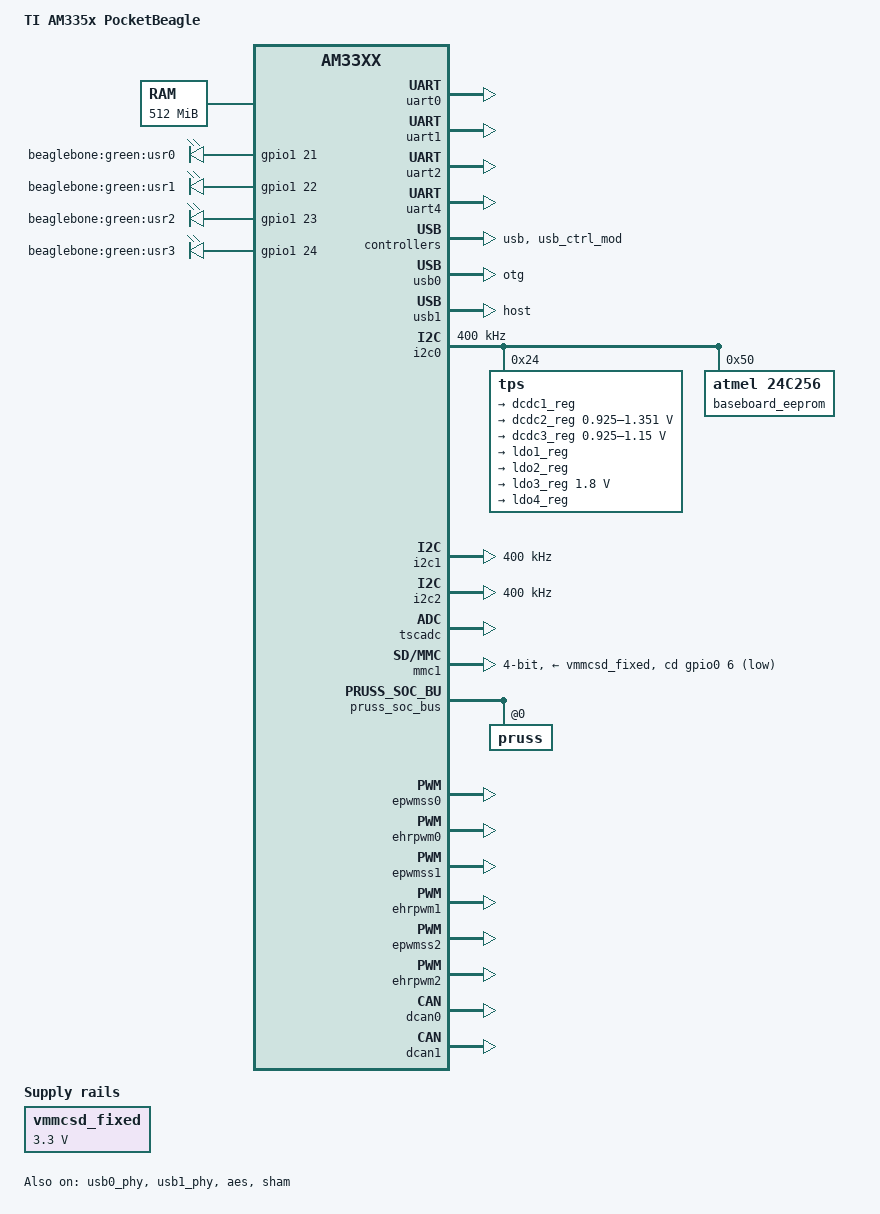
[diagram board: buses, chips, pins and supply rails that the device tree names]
/*
 * Copyright (C) 2012 Texas Instruments Incorporated - http://www.ti.com/
 *
 * This program is free software; you can redistribute it and/or modify
 * it under the terms of the GNU General Public License version 2 as
 * published by the Free Software Foundation.
 */

#include "am33xx.dtsi"

/ {
	model = "TI AM335x PocketBeagle";
	compatible = "ti,am335x-pocketbeagle", "ti,am335x-bone", "ti,am33xx";

	cpus {
		cpu@0 {
			cpu0-supply = <&dcdc2_reg>;
		};
	};

	memory@80000000 {
		device_type = "memory";
		reg = <0x80000000 0x20000000>; /* 512 MB */
	};

	chosen {
		stdout-path = &uart0;
	};

	leds {
		pinctrl-names = "default", "sleep";
		pinctrl-0 = <&user_leds_default>;
		pinctrl-1 = <&user_leds_sleep>;

		compatible = "gpio-leds";

		led@2 {
			label = "beaglebone:green:usr0";
			gpios = <&gpio1 21 GPIO_ACTIVE_HIGH>;
			linux,default-trigger = "heartbeat";
			default-state = "off";
		};

		led@3 {
			label = "beaglebone:green:usr1";
			gpios = <&gpio1 22 GPIO_ACTIVE_HIGH>;
			linux,default-trigger = "mmc0";
			default-state = "off";
		};

		led@4 {
			label = "beaglebone:green:usr2";
			gpios = <&gpio1 23 GPIO_ACTIVE_HIGH>;
			linux,default-trigger = "cpu0";
			default-state = "off";
		};

		led@5 {
			label = "beaglebone:green:usr3";
			gpios = <&gpio1 24 GPIO_ACTIVE_HIGH>;
			linux,default-trigger = "mmc1";
			default-state = "off";
		};
	};

	vmmcsd_fixed: fixedregulator0 {
		compatible = "regulator-fixed";
		regulator-name = "vmmcsd_fixed";
		regulator-min-microvolt = <3300000>;
		regulator-max-microvolt = <3300000>;
	};
};

&cpu0_opp_table {
	/*
	* All PG 2.0 silicon may not support 1GHz but some of the early
	* BeagleBone Blacks have PG 2.0 silicon which is guaranteed
	* to support 1GHz OPP so enable it for PG 2.0 on this board.
	*/
	oppnitro-1000000000 {
		opp-supported-hw = <0x06 0x0100>;
	};
};

&am33xx_pinmux {
	user_leds_default: user_leds_default {
		pinctrl-single,pins = <
			AM33XX_IOPAD(0x0854, PIN_OUTPUT_PULLDOWN | MUX_MODE7)	/* gpmc_a5.gpio1_21 */
			AM33XX_IOPAD(0x0858, PIN_OUTPUT_PULLUP | MUX_MODE7)	/* gpmc_a6.gpio1_22 */
			AM33XX_IOPAD(0x085c, PIN_OUTPUT_PULLDOWN | MUX_MODE7)	/* gpmc_a7.gpio1_23 */
			AM33XX_IOPAD(0x0860, PIN_OUTPUT_PULLUP | MUX_MODE7)	/* gpmc_a8.gpio1_24 */
		>;
	};

	user_leds_sleep: user_leds_sleep {
		pinctrl-single,pins = <
			AM33XX_IOPAD(0x0854, PIN_INPUT_PULLDOWN | MUX_MODE7)	/* gpmc_a5.gpio1_21 */
			AM33XX_IOPAD(0x0858, PIN_INPUT_PULLDOWN | MUX_MODE7)	/* gpmc_a6.gpio1_22 */
			AM33XX_IOPAD(0x085c, PIN_INPUT_PULLDOWN | MUX_MODE7)	/* gpmc_a7.gpio1_23 */
			AM33XX_IOPAD(0x0860, PIN_INPUT_PULLDOWN | MUX_MODE7)	/* gpmc_a8.gpio1_24 */
		>;
	};

	i2c0_pins: pinmux_i2c0_pins {
		pinctrl-single,pins = <
			AM33XX_IOPAD(0x0988, PIN_INPUT_PULLUP | MUX_MODE0)	/* i2c0_sda.i2c0_sda */
			AM33XX_IOPAD(0x098c, PIN_INPUT_PULLUP | MUX_MODE0)	/* i2c0_scl.i2c0_scl */
		>;
	};

	mmc0_pins: pinmux_mmc0_pins {
		pinctrl-single,pins = <
			AM33XX_IOPAD(0x0960, PIN_INPUT | MUX_MODE7) /* GPIO0_6 */
		>;
	};

	/************************/
	/* P1 Header */
	/************************/

	/* P1_01                VIN-AC */

	/* P1_02 (ZCZ ball R5) gpio2_23 */
	P1_02_default_pin: pinmux_P1_02_default_pin { pinctrl-single,pins = <
		AM33XX_IOPAD(0x08e4, PIN_INPUT | MUX_MODE7) >; };			/* lcd_hsync.gpio2_23 */
	P1_02_gpio_pin: pinmux_P1_02_gpio_pin { pinctrl-single,pins = <
		AM33XX_IOPAD(0x08e4, PIN_OUTPUT | INPUT_EN | MUX_MODE7) >; };		/* lcd_hsync.gpio2_23 */
	P1_02_gpio_pu_pin: pinmux_P1_02_gpio_pu_pin { pinctrl-single,pins = <
		AM33XX_IOPAD(0x08e4, PIN_OUTPUT_PULLUP | INPUT_EN | MUX_MODE7) >; };	/* lcd_hsync.gpio2_23 */
	P1_02_gpio_pd_pin: pinmux_P1_02_gpio_pd_pin { pinctrl-single,pins = <
		AM33XX_IOPAD(0x08e4, PIN_OUTPUT_PULLDOWN | INPUT_EN | MUX_MODE7) >; };	/* lcd_hsync.gpio2_23 */
	P1_02_gpio_input_pin: pinmux_P1_02_gpio_input_pin { pinctrl-single,pins = <
		AM33XX_IOPAD(0x08e4, PIN_INPUT | MUX_MODE7) >; };			/* lcd_hsync.gpio2_23 */
	P1_02_pruout_pin: pinmux_P1_02_pruout_pin { pinctrl-single,pins = <
		AM33XX_IOPAD(0x08e4, PIN_OUTPUT_PULLDOWN | INPUT_EN | MUX_MODE5) >; };	/* lcd_hsync.pru1_out9 */
	P1_02_pruin_pin: pinmux_P1_02_pruin_pin { pinctrl-single,pins = <
		AM33XX_IOPAD(0x08e4, PIN_INPUT | MUX_MODE6) >; };			/* lcd_hsync.pru1_in9 */

	/* P1_03 (ZCZ ball F15)  usb1_vbus_out         */

	/* P1_04 (ZCZ ball R6) gpio2_25 */
	P1_04_default_pin: pinmux_P1_04_default_pin { pinctrl-single,pins = <
		AM33XX_IOPAD(0x08ec, PIN_OUTPUT_PULLDOWN | INPUT_EN | MUX_MODE7) >; };	/* lcd_ac_bias_en.gpio2_25 */
	P1_04_gpio_pin: pinmux_P1_04_gpio_pin { pinctrl-single,pins = <
		AM33XX_IOPAD(0x08ec, PIN_OUTPUT | INPUT_EN | MUX_MODE7) >; };		/* lcd_ac_bias_en.gpio2_25 */
	P1_04_gpio_pu_pin: pinmux_P1_04_gpio_pu_pin { pinctrl-single,pins = <
		AM33XX_IOPAD(0x08ec, PIN_OUTPUT_PULLUP | INPUT_EN | MUX_MODE7) >; };	/* lcd_ac_bias_en.gpio2_25 */
	P1_04_gpio_pd_pin: pinmux_P1_04_gpio_pd_pin { pinctrl-single,pins = <
		AM33XX_IOPAD(0x08ec, PIN_OUTPUT_PULLDOWN | INPUT_EN | MUX_MODE7) >; };	/* lcd_ac_bias_en.gpio2_25 */
	P1_04_gpio_input_pin: pinmux_P1_04_gpio_input_pin { pinctrl-single,pins = <
		AM33XX_IOPAD(0x08ec, PIN_INPUT | MUX_MODE7) >; };			/* lcd_ac_bias_en.gpio2_25 */
	P1_04_pruout_pin: pinmux_P1_04_pruout_pin { pinctrl-single,pins = <
		AM33XX_IOPAD(0x08ec, PIN_OUTPUT_PULLDOWN | INPUT_EN | MUX_MODE5) >; };	/* lcd_ac_bias_en.pru1_out11 */
	P1_04_pruin_pin: pinmux_P1_04_pruin_pin { pinctrl-single,pins = <
		AM33XX_IOPAD(0x08ec, PIN_INPUT | MUX_MODE6) >; };			/* lcd_ac_bias_en.pru1_in11 */

	/* P1_05 (ZCZ ball T18)  usb1_vbus_in         */

	/* P1_06 (ZCZ ball A16) spi0_cs0 */
	P1_06_default_pin: pinmux_P1_06_default_pin { pinctrl-single,pins = <
		AM33XX_IOPAD(0x095c, PIN_OUTPUT_PULLUP | INPUT_EN | MUX_MODE0) >; };	/* spi0_cs0.spi0_cs0 */
	P1_06_gpio_pin: pinmux_P1_06_gpio_pin { pinctrl-single,pins = <
		AM33XX_IOPAD(0x095c, PIN_OUTPUT | INPUT_EN | MUX_MODE7) >; };		/* spi0_cs0.gpio0_5 */
	P1_06_gpio_pu_pin: pinmux_P1_06_gpio_pu_pin { pinctrl-single,pins = <
		AM33XX_IOPAD(0x095c, PIN_OUTPUT_PULLUP | INPUT_EN | MUX_MODE7) >; };	/* spi0_cs0.gpio0_5 */
	P1_06_gpio_pd_pin: pinmux_P1_06_gpio_pd_pin { pinctrl-single,pins = <
		AM33XX_IOPAD(0x095c, PIN_OUTPUT_PULLDOWN | INPUT_EN | MUX_MODE7) >; };	/* spi0_cs0.gpio0_5 */
	P1_06_gpio_input_pin: pinmux_P1_06_gpio_input_pin { pinctrl-single,pins = <
		AM33XX_IOPAD(0x095c, PIN_INPUT | MUX_MODE7) >; };			/* spi0_cs0.gpio0_5 */
	P1_06_spi_cs_pin: pinmux_P1_06_spi_cs_pin { pinctrl-single,pins = <
		AM33XX_IOPAD(0x095c, PIN_OUTPUT_PULLUP | INPUT_EN | MUX_MODE0) >; };	/* spi0_cs0.spi0_cs0 */
	P1_06_i2c_pin: pinmux_P1_06_i2c_pin { pinctrl-single,pins = <
		AM33XX_IOPAD(0x095c, PIN_OUTPUT_PULLUP | INPUT_EN | MUX_MODE2) >; };	/* spi0_cs0.i2c1_scl */
	P1_06_pwm_pin: pinmux_P1_06_pwm_pin { pinctrl-single,pins = <
		AM33XX_IOPAD(0x095c, PIN_OUTPUT_PULLDOWN | INPUT_EN | MUX_MODE3) >; };	/* spi0_cs0.ehrpwm0_synci */
	P1_06_pru_uart_pin: pinmux_P1_06_pru_uart_pin { pinctrl-single,pins = <
		AM33XX_IOPAD(0x095c, PIN_OUTPUT_PULLUP | INPUT_EN | MUX_MODE4) >; };	/* spi0_cs0.pr1_uart0_txd */

	/* P1_07                VIN-USB */

	/* P1_08 (ZCZ ball A17) spi0_sclk */
	P1_08_default_pin: pinmux_P1_08_default_pin { pinctrl-single,pins = <
		AM33XX_IOPAD(0x0950, PIN_OUTPUT_PULLUP | INPUT_EN | MUX_MODE0) >; };	/* spi0_sclk.spi0_sclk */
	P1_08_gpio_pin: pinmux_P1_08_gpio_pin { pinctrl-single,pins = <
		AM33XX_IOPAD(0x0950, PIN_OUTPUT | INPUT_EN | MUX_MODE7) >; };		/* spi0_sclk.gpio0_2 */
	P1_08_gpio_pu_pin: pinmux_P1_08_gpio_pu_pin { pinctrl-single,pins = <
		AM33XX_IOPAD(0x0950, PIN_OUTPUT_PULLUP | INPUT_EN | MUX_MODE7) >; };	/* spi0_sclk.gpio0_2 */
	P1_08_gpio_pd_pin: pinmux_P1_08_gpio_pd_pin { pinctrl-single,pins = <
		AM33XX_IOPAD(0x0950, PIN_OUTPUT_PULLDOWN | INPUT_EN | MUX_MODE7) >; };	/* spi0_sclk.gpio0_2 */
	P1_08_gpio_input_pin: pinmux_P1_08_gpio_input_pin { pinctrl-single,pins = <
		AM33XX_IOPAD(0x0950, PIN_INPUT | MUX_MODE7) >; };			/* spi0_sclk.gpio0_2 */
	P1_08_spi_sclk_pin: pinmux_P1_08_spi_sclk_pin { pinctrl-single,pins = <
		AM33XX_IOPAD(0x0950, PIN_OUTPUT_PULLUP | INPUT_EN | MUX_MODE0) >; };	/* spi0_sclk.spi0_sclk */
	P1_08_uart_pin: pinmux_P1_08_uart_pin { pinctrl-single,pins = <
		AM33XX_IOPAD(0x0950, PIN_OUTPUT_PULLUP | INPUT_EN | MUX_MODE1) >; };	/* spi0_sclk.uart2_rxd */
	P1_08_i2c_pin: pinmux_P1_08_i2c_pin { pinctrl-single,pins = <
		AM33XX_IOPAD(0x0950, PIN_OUTPUT_PULLUP | INPUT_EN | MUX_MODE2) >; };	/* spi0_sclk.i2c2_sda */
	P1_08_pwm_pin: pinmux_P1_08_pwm_pin { pinctrl-single,pins = <
		AM33XX_IOPAD(0x0950, PIN_OUTPUT_PULLDOWN | INPUT_EN | MUX_MODE3) >; };	/* spi0_sclk.ehrpwm0a */
	P1_08_pru_uart_pin: pinmux_P1_08_pru_uart_pin { pinctrl-single,pins = <
		AM33XX_IOPAD(0x0950, PIN_OUTPUT_PULLUP | INPUT_EN | MUX_MODE4) >; };	/* spi0_sclk.pr1_uart0_cts_n */

	/* P1_09 (ZCZ ball R18)  USB1-DN         */

	/* P1_10 (ZCZ ball B17) spi0_d0 */
	P1_10_default_pin: pinmux_P1_10_default_pin { pinctrl-single,pins = <
		AM33XX_IOPAD(0x0954, PIN_OUTPUT_PULLUP | INPUT_EN | MUX_MODE0) >; };	/* spi0_d0.spi0_d0 */
	P1_10_gpio_pin: pinmux_P1_10_gpio_pin { pinctrl-single,pins = <
		AM33XX_IOPAD(0x0954, PIN_OUTPUT | INPUT_EN | MUX_MODE7) >; };		/* spi0_d0.gpio0_3 */
	P1_10_gpio_pu_pin: pinmux_P1_10_gpio_pu_pin { pinctrl-single,pins = <
		AM33XX_IOPAD(0x0954, PIN_OUTPUT_PULLUP | INPUT_EN | MUX_MODE7) >; };	/* spi0_d0.gpio0_3 */
	P1_10_gpio_pd_pin: pinmux_P1_10_gpio_pd_pin { pinctrl-single,pins = <
		AM33XX_IOPAD(0x0954, PIN_OUTPUT_PULLDOWN | INPUT_EN | MUX_MODE7) >; };	/* spi0_d0.gpio0_3 */
	P1_10_gpio_input_pin: pinmux_P1_10_gpio_input_pin { pinctrl-single,pins = <
		AM33XX_IOPAD(0x0954, PIN_INPUT | MUX_MODE7) >; };			/* spi0_d0.gpio0_3 */
	P1_10_spi_pin: pinmux_P1_10_spi_pin { pinctrl-single,pins = <
		AM33XX_IOPAD(0x0954, PIN_OUTPUT_PULLUP | INPUT_EN | MUX_MODE0) >; };	/* spi0_d0.spi0_d0 */
	P1_10_uart_pin: pinmux_P1_10_uart_pin { pinctrl-single,pins = <
		AM33XX_IOPAD(0x0954, PIN_OUTPUT_PULLUP | INPUT_EN | MUX_MODE1) >; };	/* spi0_d0.uart2_txd */
	P1_10_i2c_pin: pinmux_P1_10_i2c_pin { pinctrl-single,pins = <
		AM33XX_IOPAD(0x0954, PIN_OUTPUT_PULLUP | INPUT_EN | MUX_MODE2) >; };	/* spi0_d0.i2c2_scl */
	P1_10_pwm_pin: pinmux_P1_10_pwm_pin { pinctrl-single,pins = <
		AM33XX_IOPAD(0x0954, PIN_OUTPUT_PULLDOWN | INPUT_EN | MUX_MODE3) >; };	/* spi0_d0.ehrpwm0b */
	P1_10_pru_uart_pin: pinmux_P1_10_pru_uart_pin { pinctrl-single,pins = <
		AM33XX_IOPAD(0x0954, PIN_OUTPUT_PULLUP | INPUT_EN | MUX_MODE4) >; };	/* spi0_d0.pr1_uart0_rts_n */

	/* P1_11 (ZCZ ball R17)  USB1-DP         */

	/* P1_12 (ZCZ ball B16) spi0_d1 */
	P1_12_default_pin: pinmux_P1_12_default_pin { pinctrl-single,pins = <
		AM33XX_IOPAD(0x0958, PIN_OUTPUT_PULLUP | INPUT_EN | MUX_MODE0) >; };	/* spi0_d1.spi0_d1 */
	P1_12_gpio_pin: pinmux_P1_12_gpio_pin { pinctrl-single,pins = <
		AM33XX_IOPAD(0x0958, PIN_OUTPUT | INPUT_EN | MUX_MODE7) >; };		/* spi0_d1.gpio0_4 */
	P1_12_gpio_pu_pin: pinmux_P1_12_gpio_pu_pin { pinctrl-single,pins = <
		AM33XX_IOPAD(0x0958, PIN_OUTPUT_PULLUP | INPUT_EN | MUX_MODE7) >; };	/* spi0_d1.gpio0_4 */
	P1_12_gpio_pd_pin: pinmux_P1_12_gpio_pd_pin { pinctrl-single,pins = <
		AM33XX_IOPAD(0x0958, PIN_OUTPUT_PULLDOWN | INPUT_EN | MUX_MODE7) >; };	/* spi0_d1.gpio0_4 */
	P1_12_gpio_input_pin: pinmux_P1_12_gpio_input_pin { pinctrl-single,pins = <
		AM33XX_IOPAD(0x0958, PIN_INPUT | MUX_MODE7) >; };			/* spi0_d1.gpio0_4 */
	P1_12_spi_pin: pinmux_P1_12_spi_pin { pinctrl-single,pins = <
		AM33XX_IOPAD(0x0958, PIN_OUTPUT_PULLUP | INPUT_EN | MUX_MODE0) >; };	/* spi0_d1.spi0_d1 */
	P1_12_i2c_pin: pinmux_P1_12_i2c_pin { pinctrl-single,pins = <
		AM33XX_IOPAD(0x0958, PIN_OUTPUT_PULLUP | INPUT_EN | MUX_MODE2) >; };	/* spi0_d1.i2c1_sda */
	P1_12_pwm_pin: pinmux_P1_12_pwm_pin { pinctrl-single,pins = <
		AM33XX_IOPAD(0x0958, PIN_OUTPUT_PULLDOWN | INPUT_EN | MUX_MODE3) >; };	/* spi0_d1.ehrpwm0_tripzone_input */
	P1_12_pru_uart_pin: pinmux_P1_12_pru_uart_pin { pinctrl-single,pins = <
		AM33XX_IOPAD(0x0958, PIN_OUTPUT_PULLUP | INPUT_EN | MUX_MODE4) >; };	/* spi0_d1.pr1_uart0_rxd */

	/* P1_13 (ZCZ ball P17)  USB1-ID         */

	/* P1_14                VOUT-3.3V */

	/* P1_15                GND */

	/* P1_16                GND */

	/* P1_17 (ZCZ ball A9)  VREFN         */

	/* P1_18 (ZCZ ball B9)  VREFP         */

	/* P1_19 (ZCZ ball B6)  AIN0         */

	/* P1_20 (ZCZ ball D14) gpio0_20 */
	P1_20_default_pin: pinmux_P1_20_default_pin { pinctrl-single,pins = <
		AM33XX_IOPAD(0x09b4, PIN_OUTPUT_PULLDOWN | INPUT_EN | MUX_MODE7) >; };	/* xdma_event_intr1.gpio0_20 */
	P1_20_gpio_pin: pinmux_P1_20_gpio_pin { pinctrl-single,pins = <
		AM33XX_IOPAD(0x09b4, PIN_OUTPUT | INPUT_EN | MUX_MODE7) >; };		/* xdma_event_intr1.gpio0_20 */
	P1_20_gpio_pu_pin: pinmux_P1_20_gpio_pu_pin { pinctrl-single,pins = <
		AM33XX_IOPAD(0x09b4, PIN_OUTPUT_PULLUP | INPUT_EN | MUX_MODE7) >; };	/* xdma_event_intr1.gpio0_20 */
	P1_20_gpio_pd_pin: pinmux_P1_20_gpio_pd_pin { pinctrl-single,pins = <
		AM33XX_IOPAD(0x09b4, PIN_OUTPUT_PULLDOWN | INPUT_EN | MUX_MODE7) >; };	/* xdma_event_intr1.gpio0_20 */
	P1_20_gpio_input_pin: pinmux_P1_20_gpio_input_pin { pinctrl-single,pins = <
		AM33XX_IOPAD(0x09b4, PIN_INPUT | MUX_MODE7) >; };			/* xdma_event_intr1.gpio0_20 */
	P1_20_pruin_pin: pinmux_P1_20_pruin_pin { pinctrl-single,pins = <
		AM33XX_IOPAD(0x09b4, PIN_INPUT | MUX_MODE5) >; };			/* xdma_event_intr1.pru0_in16 */

	/* P1_21 (ZCZ ball C7)  AIN1         */

	/* P1_22                GND */

	/* P1_23 (ZCZ ball B7)  AIN2         */

	/* P1_24                VOUT-5V */

	/* P1_25 (ZCZ ball A7)  AIN3         */

	/* P1_26 (ZCZ ball D18) i2c2_sda */
	P1_26_default_pin: pinmux_P1_26_default_pin { pinctrl-single,pins = <
		AM33XX_IOPAD(0x0978, PIN_OUTPUT_PULLUP | INPUT_EN | MUX_MODE3) >; };	/* uart1_ctsn.i2c2_sda */
	P1_26_gpio_pin: pinmux_P1_26_gpio_pin { pinctrl-single,pins = <
		AM33XX_IOPAD(0x0978, PIN_OUTPUT | INPUT_EN | MUX_MODE7) >; };		/* uart1_ctsn.gpio0_12 */
	P1_26_gpio_pu_pin: pinmux_P1_26_gpio_pu_pin { pinctrl-single,pins = <
		AM33XX_IOPAD(0x0978, PIN_OUTPUT_PULLUP | INPUT_EN | MUX_MODE7) >; };	/* uart1_ctsn.gpio0_12 */
	P1_26_gpio_pd_pin: pinmux_P1_26_gpio_pd_pin { pinctrl-single,pins = <
		AM33XX_IOPAD(0x0978, PIN_OUTPUT_PULLDOWN | INPUT_EN | MUX_MODE7) >; };	/* uart1_ctsn.gpio0_12 */
	P1_26_gpio_input_pin: pinmux_P1_26_gpio_input_pin { pinctrl-single,pins = <
		AM33XX_IOPAD(0x0978, PIN_INPUT | MUX_MODE7) >; };			/* uart1_ctsn.gpio0_12 */
	P1_26_can_pin: pinmux_P1_26_can_pin { pinctrl-single,pins = <
		AM33XX_IOPAD(0x0978, PIN_OUTPUT_PULLUP | MUX_MODE2) >; };		/* uart1_ctsn.dcan0_tx */
	P1_26_i2c_pin: pinmux_P1_26_i2c_pin { pinctrl-single,pins = <
		AM33XX_IOPAD(0x0978, PIN_OUTPUT_PULLUP | INPUT_EN | MUX_MODE3) >; };	/* uart1_ctsn.i2c2_sda */
	P1_26_spi_cs_pin: pinmux_P1_26_spi_cs_pin { pinctrl-single,pins = <
		AM33XX_IOPAD(0x0978, PIN_OUTPUT_PULLUP | INPUT_EN | MUX_MODE4) >; };	/* uart1_ctsn.spi1_cs0 */
	P1_26_pru_uart_pin: pinmux_P1_26_pru_uart_pin { pinctrl-single,pins = <
		AM33XX_IOPAD(0x0978, PIN_OUTPUT_PULLUP | INPUT_EN | MUX_MODE5) >; };	/* uart1_ctsn.pr1_uart0_cts_n */

	/* P1_27 (ZCZ ball C8)  AIN4         */

	/* P1_28 (ZCZ ball D17) i2c2_scl */
	P1_28_default_pin: pinmux_P1_28_default_pin { pinctrl-single,pins = <
		AM33XX_IOPAD(0x097c, PIN_OUTPUT_PULLUP | INPUT_EN | MUX_MODE3) >; };	/* uart1_rtsn.i2c2_scl */
	P1_28_gpio_pin: pinmux_P1_28_gpio_pin { pinctrl-single,pins = <
		AM33XX_IOPAD(0x097c, PIN_OUTPUT | INPUT_EN | MUX_MODE7) >; };		/* uart1_rtsn.gpio0_13 */
	P1_28_gpio_pu_pin: pinmux_P1_28_gpio_pu_pin { pinctrl-single,pins = <
		AM33XX_IOPAD(0x097c, PIN_OUTPUT_PULLUP | INPUT_EN | MUX_MODE7) >; };	/* uart1_rtsn.gpio0_13 */
	P1_28_gpio_pd_pin: pinmux_P1_28_gpio_pd_pin { pinctrl-single,pins = <
		AM33XX_IOPAD(0x097c, PIN_OUTPUT_PULLDOWN | INPUT_EN | MUX_MODE7) >; };	/* uart1_rtsn.gpio0_13 */
	P1_28_gpio_input_pin: pinmux_P1_28_gpio_input_pin { pinctrl-single,pins = <
		AM33XX_IOPAD(0x097c, PIN_INPUT | MUX_MODE7) >; };			/* uart1_rtsn.gpio0_13 */
	P1_28_can_pin: pinmux_P1_28_can_pin { pinctrl-single,pins = <
		AM33XX_IOPAD(0x097c, PIN_INPUT_PULLUP | MUX_MODE2) >; };		/* uart1_rtsn.dcan0_rx */
	P1_28_i2c_pin: pinmux_P1_28_i2c_pin { pinctrl-single,pins = <
		AM33XX_IOPAD(0x097c, PIN_OUTPUT_PULLUP | INPUT_EN | MUX_MODE3) >; };	/* uart1_rtsn.i2c2_scl */
	P1_28_spi_cs_pin: pinmux_P1_28_spi_cs_pin { pinctrl-single,pins = <
		AM33XX_IOPAD(0x097c, PIN_OUTPUT_PULLUP | INPUT_EN | MUX_MODE4) >; };	/* uart1_rtsn.spi1_cs1 */
	P1_28_pru_uart_pin: pinmux_P1_28_pru_uart_pin { pinctrl-single,pins = <
		AM33XX_IOPAD(0x097c, PIN_OUTPUT_PULLUP | INPUT_EN | MUX_MODE5) >; };	/* uart1_rtsn.pr1_uart0_rts_n */

	/* P1_29 (ZCZ ball A14) pru0_in7 */
	P1_29_default_pin: pinmux_P1_29_default_pin { pinctrl-single,pins = <
		AM33XX_IOPAD(0x09ac, PIN_INPUT | MUX_MODE6) >; };			/* mcasp0_ahclkx.pru0_in7 */
	P1_29_gpio_pin: pinmux_P1_29_gpio_pin { pinctrl-single,pins = <
		AM33XX_IOPAD(0x09ac, PIN_OUTPUT | INPUT_EN | MUX_MODE7) >; };		/* mcasp0_ahclkx.gpio3_21 */
	P1_29_gpio_pu_pin: pinmux_P1_29_gpio_pu_pin { pinctrl-single,pins = <
		AM33XX_IOPAD(0x09ac, PIN_OUTPUT_PULLUP | INPUT_EN | MUX_MODE7) >; };	/* mcasp0_ahclkx.gpio3_21 */
	P1_29_gpio_pd_pin: pinmux_P1_29_gpio_pd_pin { pinctrl-single,pins = <
		AM33XX_IOPAD(0x09ac, PIN_OUTPUT_PULLDOWN | INPUT_EN | MUX_MODE7) >; };	/* mcasp0_ahclkx.gpio3_21 */
	P1_29_gpio_input_pin: pinmux_P1_29_gpio_input_pin { pinctrl-single,pins = <
		AM33XX_IOPAD(0x09ac, PIN_INPUT | MUX_MODE7) >; };			/* mcasp0_ahclkx.gpio3_21 */
	P1_29_qep_pin: pinmux_P1_29_qep_pin { pinctrl-single,pins = <
		AM33XX_IOPAD(0x09ac, PIN_OUTPUT_PULLUP | INPUT_EN | MUX_MODE1) >; };	/* mcasp0_ahclkx.eqep0_strobe */
	P1_29_pruout_pin: pinmux_P1_29_pruout_pin { pinctrl-single,pins = <
		AM33XX_IOPAD(0x09ac, PIN_OUTPUT_PULLDOWN | INPUT_EN | MUX_MODE5) >; };	/* mcasp0_ahclkx.pru0_out7 */
	P1_29_pruin_pin: pinmux_P1_29_pruin_pin { pinctrl-single,pins = <
		AM33XX_IOPAD(0x09ac, PIN_INPUT | MUX_MODE6) >; };			/* mcasp0_ahclkx.pru0_in7 */

	/* P1_30 (ZCZ ball E16) uart0_txd */
	P1_30_default_pin: pinmux_P1_30_default_pin { pinctrl-single,pins = <
		AM33XX_IOPAD(0x0974, PIN_OUTPUT_PULLUP | INPUT_EN | MUX_MODE0) >; };	/* uart0_txd.uart0_txd */
	P1_30_gpio_pin: pinmux_P1_30_gpio_pin { pinctrl-single,pins = <
		AM33XX_IOPAD(0x0974, PIN_OUTPUT | INPUT_EN | MUX_MODE7) >; };		/* uart0_txd.gpio1_11 */
	P1_30_gpio_pu_pin: pinmux_P1_30_gpio_pu_pin { pinctrl-single,pins = <
		AM33XX_IOPAD(0x0974, PIN_OUTPUT_PULLUP | INPUT_EN | MUX_MODE7) >; };	/* uart0_txd.gpio1_11 */
	P1_30_gpio_pd_pin: pinmux_P1_30_gpio_pd_pin { pinctrl-single,pins = <
		AM33XX_IOPAD(0x0974, PIN_OUTPUT_PULLDOWN | INPUT_EN | MUX_MODE7) >; };	/* uart0_txd.gpio1_11 */
	P1_30_gpio_input_pin: pinmux_P1_30_gpio_input_pin { pinctrl-single,pins = <
		AM33XX_IOPAD(0x0974, PIN_INPUT | MUX_MODE7) >; };			/* uart0_txd.gpio1_11 */
	P1_30_uart_pin: pinmux_P1_30_uart_pin { pinctrl-single,pins = <
		AM33XX_IOPAD(0x0974, PIN_OUTPUT_PULLUP | INPUT_EN | MUX_MODE0) >; };	/* uart0_txd.uart0_txd */
	P1_30_spi_cs_pin: pinmux_P1_30_spi_cs_pin { pinctrl-single,pins = <
		AM33XX_IOPAD(0x0974, PIN_OUTPUT_PULLUP | INPUT_EN | MUX_MODE1) >; };	/* uart0_txd.spi1_cs1 */
	P1_30_can_pin: pinmux_P1_30_can_pin { pinctrl-single,pins = <
		AM33XX_IOPAD(0x0974, PIN_INPUT_PULLUP | MUX_MODE2) >; };		/* uart0_txd.dcan0_rx */
	P1_30_i2c_pin: pinmux_P1_30_i2c_pin { pinctrl-single,pins = <
		AM33XX_IOPAD(0x0974, PIN_OUTPUT_PULLUP | INPUT_EN | MUX_MODE3) >; };	/* uart0_txd.i2c2_scl */
	P1_30_pruout_pin: pinmux_P1_30_pruout_pin { pinctrl-single,pins = <
		AM33XX_IOPAD(0x0974, PIN_OUTPUT_PULLDOWN | INPUT_EN | MUX_MODE5) >; };	/* uart0_txd.pru1_out15 */
	P1_30_pruin_pin: pinmux_P1_30_pruin_pin { pinctrl-single,pins = <
		AM33XX_IOPAD(0x0974, PIN_INPUT | MUX_MODE6) >; };			/* uart0_txd.pru1_in15 */

	/* P1_31 (ZCZ ball B12) pru0_in4 */
	P1_31_default_pin: pinmux_P1_31_default_pin { pinctrl-single,pins = <
		AM33XX_IOPAD(0x09a0, PIN_INPUT | MUX_MODE6) >; };			/* mcasp0_aclkr.pru0_in4 */
	P1_31_gpio_pin: pinmux_P1_31_gpio_pin { pinctrl-single,pins = <
		AM33XX_IOPAD(0x09a0, PIN_OUTPUT | INPUT_EN | MUX_MODE7) >; };		/* mcasp0_aclkr.gpio3_18 */
	P1_31_gpio_pu_pin: pinmux_P1_31_gpio_pu_pin { pinctrl-single,pins = <
		AM33XX_IOPAD(0x09a0, PIN_OUTPUT_PULLUP | INPUT_EN | MUX_MODE7) >; };	/* mcasp0_aclkr.gpio3_18 */
	P1_31_gpio_pd_pin: pinmux_P1_31_gpio_pd_pin { pinctrl-single,pins = <
		AM33XX_IOPAD(0x09a0, PIN_OUTPUT_PULLDOWN | INPUT_EN | MUX_MODE7) >; };	/* mcasp0_aclkr.gpio3_18 */
	P1_31_gpio_input_pin: pinmux_P1_31_gpio_input_pin { pinctrl-single,pins = <
		AM33XX_IOPAD(0x09a0, PIN_INPUT | MUX_MODE7) >; };			/* mcasp0_aclkr.gpio3_18 */
	P1_31_qep_pin: pinmux_P1_31_qep_pin { pinctrl-single,pins = <
		AM33XX_IOPAD(0x09a0, PIN_OUTPUT_PULLUP | INPUT_EN | MUX_MODE1) >; };	/* mcasp0_aclkr.eqep0a_in */
	P1_31_pruout_pin: pinmux_P1_31_pruout_pin { pinctrl-single,pins = <
		AM33XX_IOPAD(0x09a0, PIN_OUTPUT_PULLDOWN | INPUT_EN | MUX_MODE5) >; };	/* mcasp0_aclkr.pru0_out4 */
	P1_31_pruin_pin: pinmux_P1_31_pruin_pin { pinctrl-single,pins = <
		AM33XX_IOPAD(0x09a0, PIN_INPUT | MUX_MODE6) >; };			/* mcasp0_aclkr.pru0_in4 */

	/* P1_32 (ZCZ ball E15) uart0_rxd */
	P1_32_default_pin: pinmux_P1_32_default_pin { pinctrl-single,pins = <
		AM33XX_IOPAD(0x0970, PIN_OUTPUT_PULLUP | INPUT_EN | MUX_MODE0) >; };	/* uart0_rxd.uart0_rxd */
	P1_32_gpio_pin: pinmux_P1_32_gpio_pin { pinctrl-single,pins = <
		AM33XX_IOPAD(0x0970, PIN_OUTPUT | INPUT_EN | MUX_MODE7) >; };		/* uart0_rxd.gpio1_10 */
	P1_32_gpio_pu_pin: pinmux_P1_32_gpio_pu_pin { pinctrl-single,pins = <
		AM33XX_IOPAD(0x0970, PIN_OUTPUT_PULLUP | INPUT_EN | MUX_MODE7) >; };	/* uart0_rxd.gpio1_10 */
	P1_32_gpio_pd_pin: pinmux_P1_32_gpio_pd_pin { pinctrl-single,pins = <
		AM33XX_IOPAD(0x0970, PIN_OUTPUT_PULLDOWN | INPUT_EN | MUX_MODE7) >; };	/* uart0_rxd.gpio1_10 */
	P1_32_gpio_input_pin: pinmux_P1_32_gpio_input_pin { pinctrl-single,pins = <
		AM33XX_IOPAD(0x0970, PIN_INPUT | MUX_MODE7) >; };			/* uart0_rxd.gpio1_10 */
	P1_32_uart_pin: pinmux_P1_32_uart_pin { pinctrl-single,pins = <
		AM33XX_IOPAD(0x0970, PIN_OUTPUT_PULLUP | INPUT_EN | MUX_MODE0) >; };	/* uart0_rxd.uart0_rxd */
	P1_32_spi_cs_pin: pinmux_P1_32_spi_cs_pin { pinctrl-single,pins = <
		AM33XX_IOPAD(0x0970, PIN_OUTPUT_PULLUP | INPUT_EN | MUX_MODE1) >; };	/* uart0_rxd.spi1_cs0 */
	P1_32_can_pin: pinmux_P1_32_can_pin { pinctrl-single,pins = <
		AM33XX_IOPAD(0x0970, PIN_OUTPUT_PULLUP | MUX_MODE2) >; };		/* uart0_rxd.dcan0_tx */
	P1_32_i2c_pin: pinmux_P1_32_i2c_pin { pinctrl-single,pins = <
		AM33XX_IOPAD(0x0970, PIN_OUTPUT_PULLUP | INPUT_EN | MUX_MODE3) >; };	/* uart0_rxd.i2c2_sda */
	P1_32_pruout_pin: pinmux_P1_32_pruout_pin { pinctrl-single,pins = <
		AM33XX_IOPAD(0x0970, PIN_OUTPUT_PULLDOWN | INPUT_EN | MUX_MODE5) >; };	/* uart0_rxd.pru1_out14 */
	P1_32_pruin_pin: pinmux_P1_32_pruin_pin { pinctrl-single,pins = <
		AM33XX_IOPAD(0x0970, PIN_INPUT | MUX_MODE6) >; };			/* uart0_rxd.pru1_in14 */

	/* P1_33 (ZCZ ball B13) pru0_in1 */
	P1_33_default_pin: pinmux_P1_33_default_pin { pinctrl-single,pins = <
		AM33XX_IOPAD(0x0994, PIN_INPUT | MUX_MODE6) >; };			/* mcasp0_fsx.pru0_in1 */
	P1_33_gpio_pin: pinmux_P1_33_gpio_pin { pinctrl-single,pins = <
		AM33XX_IOPAD(0x0994, PIN_OUTPUT | INPUT_EN | MUX_MODE7) >; };		/* mcasp0_fsx.gpio3_15 */
	P1_33_gpio_pu_pin: pinmux_P1_33_gpio_pu_pin { pinctrl-single,pins = <
		AM33XX_IOPAD(0x0994, PIN_OUTPUT_PULLUP | INPUT_EN | MUX_MODE7) >; };	/* mcasp0_fsx.gpio3_15 */
	P1_33_gpio_pd_pin: pinmux_P1_33_gpio_pd_pin { pinctrl-single,pins = <
		AM33XX_IOPAD(0x0994, PIN_OUTPUT_PULLDOWN | INPUT_EN | MUX_MODE7) >; };	/* mcasp0_fsx.gpio3_15 */
	P1_33_gpio_input_pin: pinmux_P1_33_gpio_input_pin { pinctrl-single,pins = <
		AM33XX_IOPAD(0x0994, PIN_INPUT | MUX_MODE7) >; };			/* mcasp0_fsx.gpio3_15 */
	P1_33_pwm_pin: pinmux_P1_33_pwm_pin { pinctrl-single,pins = <
		AM33XX_IOPAD(0x0994, PIN_OUTPUT_PULLDOWN | INPUT_EN | MUX_MODE1) >; };	/* mcasp0_fsx.ehrpwm0b */
	P1_33_spi_pin: pinmux_P1_33_spi_pin { pinctrl-single,pins = <
		AM33XX_IOPAD(0x0994, PIN_OUTPUT_PULLUP | INPUT_EN | MUX_MODE3) >; };	/* mcasp0_fsx.spi1_d0 */
	P1_33_pruout_pin: pinmux_P1_33_pruout_pin { pinctrl-single,pins = <
		AM33XX_IOPAD(0x0994, PIN_OUTPUT_PULLDOWN | INPUT_EN | MUX_MODE5) >; };	/* mcasp0_fsx.pru0_out1 */
	P1_33_pruin_pin: pinmux_P1_33_pruin_pin { pinctrl-single,pins = <
		AM33XX_IOPAD(0x0994, PIN_INPUT | MUX_MODE6) >; };			/* mcasp0_fsx.pru0_in1 */

	/* P1_34 (ZCZ ball T11) gpio0_26 */
	P1_34_default_pin: pinmux_P1_34_default_pin { pinctrl-single,pins = <
		AM33XX_IOPAD(0x0828, PIN_OUTPUT_PULLDOWN | INPUT_EN | MUX_MODE7) >; };	/* gpmc_ad10.gpio0_26 */
	P1_34_gpio_pin: pinmux_P1_34_gpio_pin { pinctrl-single,pins = <
		AM33XX_IOPAD(0x0828, PIN_OUTPUT | INPUT_EN | MUX_MODE7) >; };		/* gpmc_ad10.gpio0_26 */
	P1_34_gpio_pu_pin: pinmux_P1_34_gpio_pu_pin { pinctrl-single,pins = <
		AM33XX_IOPAD(0x0828, PIN_OUTPUT_PULLUP | INPUT_EN | MUX_MODE7) >; };	/* gpmc_ad10.gpio0_26 */
	P1_34_gpio_pd_pin: pinmux_P1_34_gpio_pd_pin { pinctrl-single,pins = <
		AM33XX_IOPAD(0x0828, PIN_OUTPUT_PULLDOWN | INPUT_EN | MUX_MODE7) >; };	/* gpmc_ad10.gpio0_26 */
	P1_34_gpio_input_pin: pinmux_P1_34_gpio_input_pin { pinctrl-single,pins = <
		AM33XX_IOPAD(0x0828, PIN_INPUT | MUX_MODE7) >; };			/* gpmc_ad10.gpio0_26 */
	P1_34_pwm_pin: pinmux_P1_34_pwm_pin { pinctrl-single,pins = <
		AM33XX_IOPAD(0x0828, PIN_OUTPUT_PULLDOWN | INPUT_EN | MUX_MODE4) >; };	/* gpmc_ad10.ehrpwm2_tripzone_input */

	/* P1_35 (ZCZ ball V5) pru1_in10 */
	P1_35_default_pin: pinmux_P1_35_default_pin { pinctrl-single,pins = <
		AM33XX_IOPAD(0x08e8, PIN_INPUT | MUX_MODE6) >; };			/* lcd_pclk.pru1_in10 */
	P1_35_gpio_pin: pinmux_P1_35_gpio_pin { pinctrl-single,pins = <
		AM33XX_IOPAD(0x08e8, PIN_OUTPUT | INPUT_EN | MUX_MODE7) >; };		/* lcd_pclk.gpio2_24 */
	P1_35_gpio_pu_pin: pinmux_P1_35_gpio_pu_pin { pinctrl-single,pins = <
		AM33XX_IOPAD(0x08e8, PIN_OUTPUT_PULLUP | INPUT_EN | MUX_MODE7) >; };	/* lcd_pclk.gpio2_24 */
	P1_35_gpio_pd_pin: pinmux_P1_35_gpio_pd_pin { pinctrl-single,pins = <
		AM33XX_IOPAD(0x08e8, PIN_OUTPUT_PULLDOWN | INPUT_EN | MUX_MODE7) >; };	/* lcd_pclk.gpio2_24 */
	P1_35_gpio_input_pin: pinmux_P1_35_gpio_input_pin { pinctrl-single,pins = <
		AM33XX_IOPAD(0x08e8, PIN_INPUT | MUX_MODE7) >; };			/* lcd_pclk.gpio2_24 */
	P1_35_pruout_pin: pinmux_P1_35_pruout_pin { pinctrl-single,pins = <
		AM33XX_IOPAD(0x08e8, PIN_OUTPUT_PULLDOWN | INPUT_EN | MUX_MODE5) >; };	/* lcd_pclk.pru1_out10 */
	P1_35_pruin_pin: pinmux_P1_35_pruin_pin { pinctrl-single,pins = <
		AM33XX_IOPAD(0x08e8, PIN_INPUT | MUX_MODE6) >; };			/* lcd_pclk.pru1_in10 */

	/* P1_36 (ZCZ ball A13) ehrpwm0a */
	P1_36_default_pin: pinmux_P1_36_default_pin { pinctrl-single,pins = <
		AM33XX_IOPAD(0x0990, PIN_OUTPUT_PULLDOWN | INPUT_EN | MUX_MODE1) >; };	/* mcasp0_aclkx.ehrpwm0a */
	P1_36_gpio_pin: pinmux_P1_36_gpio_pin { pinctrl-single,pins = <
		AM33XX_IOPAD(0x0990, PIN_OUTPUT | INPUT_EN | MUX_MODE7) >; };		/* mcasp0_aclkx.gpio3_14 */
	P1_36_gpio_pu_pin: pinmux_P1_36_gpio_pu_pin { pinctrl-single,pins = <
		AM33XX_IOPAD(0x0990, PIN_OUTPUT_PULLUP | INPUT_EN | MUX_MODE7) >; };	/* mcasp0_aclkx.gpio3_14 */
	P1_36_gpio_pd_pin: pinmux_P1_36_gpio_pd_pin { pinctrl-single,pins = <
		AM33XX_IOPAD(0x0990, PIN_OUTPUT_PULLDOWN | INPUT_EN | MUX_MODE7) >; };	/* mcasp0_aclkx.gpio3_14 */
	P1_36_gpio_input_pin: pinmux_P1_36_gpio_input_pin { pinctrl-single,pins = <
		AM33XX_IOPAD(0x0990, PIN_INPUT | MUX_MODE7) >; };			/* mcasp0_aclkx.gpio3_14 */
	P1_36_pwm_pin: pinmux_P1_36_pwm_pin { pinctrl-single,pins = <
		AM33XX_IOPAD(0x0990, PIN_OUTPUT_PULLDOWN | INPUT_EN | MUX_MODE1) >; };	/* mcasp0_aclkx.ehrpwm0a */
	P1_36_spi_sclk_pin: pinmux_P1_36_spi_sclk_pin { pinctrl-single,pins = <
		AM33XX_IOPAD(0x0990, PIN_OUTPUT_PULLUP | INPUT_EN | MUX_MODE3) >; };	/* mcasp0_aclkx.spi1_sclk */
	P1_36_pruout_pin: pinmux_P1_36_pruout_pin { pinctrl-single,pins = <
		AM33XX_IOPAD(0x0990, PIN_OUTPUT_PULLDOWN | INPUT_EN | MUX_MODE5) >; };	/* mcasp0_aclkx.pru0_out0 */
	P1_36_pruin_pin: pinmux_P1_36_pruin_pin { pinctrl-single,pins = <
		AM33XX_IOPAD(0x0990, PIN_INPUT | MUX_MODE6) >; };			/* mcasp0_aclkx.pru0_in0 */


	/************************/
	/* P2 Header */
	/************************/

	/* P2_01 (ZCZ ball U14) ehrpwm1a */
	P2_01_default_pin: pinmux_P2_01_default_pin { pinctrl-single,pins = <
		AM33XX_IOPAD(0x0848, PIN_OUTPUT_PULLDOWN | INPUT_EN | MUX_MODE6) >; };	/* gpmc_a2.ehrpwm1a */
	P2_01_gpio_pin: pinmux_P2_01_gpio_pin { pinctrl-single,pins = <
		AM33XX_IOPAD(0x0848, PIN_OUTPUT | INPUT_EN | MUX_MODE7) >; };		/* gpmc_a2.gpio1_18 */
	P2_01_gpio_pu_pin: pinmux_P2_01_gpio_pu_pin { pinctrl-single,pins = <
		AM33XX_IOPAD(0x0848, PIN_OUTPUT_PULLUP | INPUT_EN | MUX_MODE7) >; };	/* gpmc_a2.gpio1_18 */
	P2_01_gpio_pd_pin: pinmux_P2_01_gpio_pd_pin { pinctrl-single,pins = <
		AM33XX_IOPAD(0x0848, PIN_OUTPUT_PULLDOWN | INPUT_EN | MUX_MODE7) >; };	/* gpmc_a2.gpio1_18 */
	P2_01_gpio_input_pin: pinmux_P2_01_gpio_input_pin { pinctrl-single,pins = <
		AM33XX_IOPAD(0x0848, PIN_INPUT | MUX_MODE7) >; };			/* gpmc_a2.gpio1_18 */
	P2_01_pwm_pin: pinmux_P2_01_pwm_pin { pinctrl-single,pins = <
		AM33XX_IOPAD(0x0848, PIN_OUTPUT_PULLDOWN | INPUT_EN | MUX_MODE6) >; };	/* gpmc_a2.ehrpwm1a */

	/* P2_02 (ZCZ ball V17) gpio1_27 */
	P2_02_default_pin: pinmux_P2_02_default_pin { pinctrl-single,pins = <
		AM33XX_IOPAD(0x086c, PIN_OUTPUT_PULLDOWN | INPUT_EN | MUX_MODE7) >; };	/* gpmc_a11.gpio1_27 */
	P2_02_gpio_pin: pinmux_P2_02_gpio_pin { pinctrl-single,pins = <
		AM33XX_IOPAD(0x086c, PIN_OUTPUT | INPUT_EN | MUX_MODE7) >; };		/* gpmc_a11.gpio1_27 */
	P2_02_gpio_pu_pin: pinmux_P2_02_gpio_pu_pin { pinctrl-single,pins = <
		AM33XX_IOPAD(0x086c, PIN_OUTPUT_PULLUP | INPUT_EN | MUX_MODE7) >; };	/* gpmc_a11.gpio1_27 */
	P2_02_gpio_pd_pin: pinmux_P2_02_gpio_pd_pin { pinctrl-single,pins = <
		AM33XX_IOPAD(0x086c, PIN_OUTPUT_PULLDOWN | INPUT_EN | MUX_MODE7) >; };	/* gpmc_a11.gpio1_27 */
	P2_02_gpio_input_pin: pinmux_P2_02_gpio_input_pin { pinctrl-single,pins = <
		AM33XX_IOPAD(0x086c, PIN_INPUT | MUX_MODE7) >; };			/* gpmc_a11.gpio1_27 */

	/* P2_03 (ZCZ ball T10) gpio0_23 */
	P2_03_default_pin: pinmux_P2_03_default_pin { pinctrl-single,pins = <
		AM33XX_IOPAD(0x0824, PIN_OUTPUT_PULLDOWN | INPUT_EN | MUX_MODE7) >; };	/* gpmc_ad9.gpio0_23 */
	P2_03_gpio_pin: pinmux_P2_03_gpio_pin { pinctrl-single,pins = <
		AM33XX_IOPAD(0x0824, PIN_OUTPUT | INPUT_EN | MUX_MODE7) >; };		/* gpmc_ad9.gpio0_23 */
	P2_03_gpio_pu_pin: pinmux_P2_03_gpio_pu_pin { pinctrl-single,pins = <
		AM33XX_IOPAD(0x0824, PIN_OUTPUT_PULLUP | INPUT_EN | MUX_MODE7) >; };	/* gpmc_ad9.gpio0_23 */
	P2_03_gpio_pd_pin: pinmux_P2_03_gpio_pd_pin { pinctrl-single,pins = <
		AM33XX_IOPAD(0x0824, PIN_OUTPUT_PULLDOWN | INPUT_EN | MUX_MODE7) >; };	/* gpmc_ad9.gpio0_23 */
	P2_03_gpio_input_pin: pinmux_P2_03_gpio_input_pin { pinctrl-single,pins = <
		AM33XX_IOPAD(0x0824, PIN_INPUT | MUX_MODE7) >; };			/* gpmc_ad9.gpio0_23 */
	P2_03_pwm_pin: pinmux_P2_03_pwm_pin { pinctrl-single,pins = <
		AM33XX_IOPAD(0x0824, PIN_OUTPUT_PULLDOWN | INPUT_EN | MUX_MODE4) >; };	/* gpmc_ad9.ehrpwm2b */

	/* P2_04 (ZCZ ball T16) gpio1_26 */
	P2_04_default_pin: pinmux_P2_04_default_pin { pinctrl-single,pins = <
		AM33XX_IOPAD(0x0868, PIN_OUTPUT_PULLDOWN | INPUT_EN | MUX_MODE7) >; };	/* gpmc_a10.gpio1_26 */
	P2_04_gpio_pin: pinmux_P2_04_gpio_pin { pinctrl-single,pins = <
		AM33XX_IOPAD(0x0868, PIN_OUTPUT | INPUT_EN | MUX_MODE7) >; };		/* gpmc_a10.gpio1_26 */
	P2_04_gpio_pu_pin: pinmux_P2_04_gpio_pu_pin { pinctrl-single,pins = <
		AM33XX_IOPAD(0x0868, PIN_OUTPUT_PULLUP | INPUT_EN | MUX_MODE7) >; };	/* gpmc_a10.gpio1_26 */
	P2_04_gpio_pd_pin: pinmux_P2_04_gpio_pd_pin { pinctrl-single,pins = <
		AM33XX_IOPAD(0x0868, PIN_OUTPUT_PULLDOWN | INPUT_EN | MUX_MODE7) >; };	/* gpmc_a10.gpio1_26 */
	P2_04_gpio_input_pin: pinmux_P2_04_gpio_input_pin { pinctrl-single,pins = <
		AM33XX_IOPAD(0x0868, PIN_INPUT | MUX_MODE7) >; };			/* gpmc_a10.gpio1_26 */

	/* P2_05 (ZCZ ball T17) uart4_rxd */
	P2_05_default_pin: pinmux_P2_05_default_pin { pinctrl-single,pins = <
		AM33XX_IOPAD(0x0870, PIN_OUTPUT_PULLUP | INPUT_EN | MUX_MODE6) >; };	/* gpmc_wait0.uart4_rxd */
	P2_05_gpio_pin: pinmux_P2_05_gpio_pin { pinctrl-single,pins = <
		AM33XX_IOPAD(0x0870, PIN_OUTPUT | INPUT_EN | MUX_MODE7) >; };		/* gpmc_wait0.gpio0_30 */
	P2_05_gpio_pu_pin: pinmux_P2_05_gpio_pu_pin { pinctrl-single,pins = <
		AM33XX_IOPAD(0x0870, PIN_OUTPUT_PULLUP | INPUT_EN | MUX_MODE7) >; };	/* gpmc_wait0.gpio0_30 */
	P2_05_gpio_pd_pin: pinmux_P2_05_gpio_pd_pin { pinctrl-single,pins = <
		AM33XX_IOPAD(0x0870, PIN_OUTPUT_PULLDOWN | INPUT_EN | MUX_MODE7) >; };	/* gpmc_wait0.gpio0_30 */
	P2_05_gpio_input_pin: pinmux_P2_05_gpio_input_pin { pinctrl-single,pins = <
		AM33XX_IOPAD(0x0870, PIN_INPUT | MUX_MODE7) >; };			/* gpmc_wait0.gpio0_30 */
	P2_05_uart_pin: pinmux_P2_05_uart_pin { pinctrl-single,pins = <
		AM33XX_IOPAD(0x0870, PIN_OUTPUT_PULLUP | INPUT_EN | MUX_MODE6) >; };	/* gpmc_wait0.uart4_rxd */

	/* P2_06 (ZCZ ball U16) gpio1_25 */
	P2_06_default_pin: pinmux_P2_06_default_pin { pinctrl-single,pins = <
		AM33XX_IOPAD(0x0864, PIN_OUTPUT_PULLDOWN | INPUT_EN | MUX_MODE7) >; };	/* gpmc_a9.gpio1_25 */
	P2_06_gpio_pin: pinmux_P2_06_gpio_pin { pinctrl-single,pins = <
		AM33XX_IOPAD(0x0864, PIN_OUTPUT | INPUT_EN | MUX_MODE7) >; };		/* gpmc_a9.gpio1_25 */
	P2_06_gpio_pu_pin: pinmux_P2_06_gpio_pu_pin { pinctrl-single,pins = <
		AM33XX_IOPAD(0x0864, PIN_OUTPUT_PULLUP | INPUT_EN | MUX_MODE7) >; };	/* gpmc_a9.gpio1_25 */
	P2_06_gpio_pd_pin: pinmux_P2_06_gpio_pd_pin { pinctrl-single,pins = <
		AM33XX_IOPAD(0x0864, PIN_OUTPUT_PULLDOWN | INPUT_EN | MUX_MODE7) >; };	/* gpmc_a9.gpio1_25 */
	P2_06_gpio_input_pin: pinmux_P2_06_gpio_input_pin { pinctrl-single,pins = <
		AM33XX_IOPAD(0x0864, PIN_INPUT | MUX_MODE7) >; };			/* gpmc_a9.gpio1_25 */

	/* P2_07 (ZCZ ball U17) uart4_txd */
	P2_07_default_pin: pinmux_P2_07_default_pin { pinctrl-single,pins = <
		AM33XX_IOPAD(0x0874, PIN_OUTPUT_PULLUP | INPUT_EN | MUX_MODE6) >; };	/* gpmc_wpn.uart4_txd */
	P2_07_gpio_pin: pinmux_P2_07_gpio_pin { pinctrl-single,pins = <
		AM33XX_IOPAD(0x0874, PIN_OUTPUT | INPUT_EN | MUX_MODE7) >; };		/* gpmc_wpn.gpio0_31 */
	P2_07_gpio_pu_pin: pinmux_P2_07_gpio_pu_pin { pinctrl-single,pins = <
		AM33XX_IOPAD(0x0874, PIN_OUTPUT_PULLUP | INPUT_EN | MUX_MODE7) >; };	/* gpmc_wpn.gpio0_31 */
	P2_07_gpio_pd_pin: pinmux_P2_07_gpio_pd_pin { pinctrl-single,pins = <
		AM33XX_IOPAD(0x0874, PIN_OUTPUT_PULLDOWN | INPUT_EN | MUX_MODE7) >; };	/* gpmc_wpn.gpio0_31 */
	P2_07_gpio_input_pin: pinmux_P2_07_gpio_input_pin { pinctrl-single,pins = <
		AM33XX_IOPAD(0x0874, PIN_INPUT | MUX_MODE7) >; };			/* gpmc_wpn.gpio0_31 */
	P2_07_uart_pin: pinmux_P2_07_uart_pin { pinctrl-single,pins = <
		AM33XX_IOPAD(0x0874, PIN_OUTPUT_PULLUP | INPUT_EN | MUX_MODE6) >; };	/* gpmc_wpn.uart4_txd */

	/* P2_08 (ZCZ ball U18) gpio1_28 */
	P2_08_default_pin: pinmux_P2_08_default_pin { pinctrl-single,pins = <
		AM33XX_IOPAD(0x0878, PIN_OUTPUT_PULLUP | INPUT_EN | MUX_MODE7) >; };	/* gpmc_be1n.gpio1_28 */
	P2_08_gpio_pin: pinmux_P2_08_gpio_pin { pinctrl-single,pins = <
		AM33XX_IOPAD(0x0878, PIN_OUTPUT | INPUT_EN | MUX_MODE7) >; };		/* gpmc_be1n.gpio1_28 */
	P2_08_gpio_pu_pin: pinmux_P2_08_gpio_pu_pin { pinctrl-single,pins = <
		AM33XX_IOPAD(0x0878, PIN_OUTPUT_PULLUP | INPUT_EN | MUX_MODE7) >; };	/* gpmc_be1n.gpio1_28 */
	P2_08_gpio_pd_pin: pinmux_P2_08_gpio_pd_pin { pinctrl-single,pins = <
		AM33XX_IOPAD(0x0878, PIN_OUTPUT_PULLDOWN | INPUT_EN | MUX_MODE7) >; };	/* gpmc_be1n.gpio1_28 */
	P2_08_gpio_input_pin: pinmux_P2_08_gpio_input_pin { pinctrl-single,pins = <
		AM33XX_IOPAD(0x0878, PIN_INPUT | MUX_MODE7) >; };			/* gpmc_be1n.gpio1_28 */

	/* P2_09 (ZCZ ball D15) i2c1_scl */
	P2_09_default_pin: pinmux_P2_09_default_pin { pinctrl-single,pins = <
		AM33XX_IOPAD(0x0984, PIN_OUTPUT_PULLUP | INPUT_EN | MUX_MODE3) >; };	/* uart1_txd.i2c1_scl */
	P2_09_gpio_pin: pinmux_P2_09_gpio_pin { pinctrl-single,pins = <
		AM33XX_IOPAD(0x0984, PIN_OUTPUT | INPUT_EN | MUX_MODE7) >; };		/* uart1_txd.gpio0_15 */
	P2_09_gpio_pu_pin: pinmux_P2_09_gpio_pu_pin { pinctrl-single,pins = <
		AM33XX_IOPAD(0x0984, PIN_OUTPUT_PULLUP | INPUT_EN | MUX_MODE7) >; };	/* uart1_txd.gpio0_15 */
	P2_09_gpio_pd_pin: pinmux_P2_09_gpio_pd_pin { pinctrl-single,pins = <
		AM33XX_IOPAD(0x0984, PIN_OUTPUT_PULLDOWN | INPUT_EN | MUX_MODE7) >; };	/* uart1_txd.gpio0_15 */
	P2_09_gpio_input_pin: pinmux_P2_09_gpio_input_pin { pinctrl-single,pins = <
		AM33XX_IOPAD(0x0984, PIN_INPUT | MUX_MODE7) >; };			/* uart1_txd.gpio0_15 */
	P2_09_uart_pin: pinmux_P2_09_uart_pin { pinctrl-single,pins = <
		AM33XX_IOPAD(0x0984, PIN_OUTPUT_PULLUP | INPUT_EN | MUX_MODE0) >; };	/* uart1_txd.uart1_txd */
	P2_09_can_pin: pinmux_P2_09_can_pin { pinctrl-single,pins = <
		AM33XX_IOPAD(0x0984, PIN_INPUT_PULLUP | MUX_MODE2) >; };		/* uart1_txd.dcan1_rx */
	P2_09_i2c_pin: pinmux_P2_09_i2c_pin { pinctrl-single,pins = <
		AM33XX_IOPAD(0x0984, PIN_OUTPUT_PULLUP | INPUT_EN | MUX_MODE3) >; };	/* uart1_txd.i2c1_scl */
	P2_09_pru_uart_pin: pinmux_P2_09_pru_uart_pin { pinctrl-single,pins = <
		AM33XX_IOPAD(0x0984, PIN_OUTPUT_PULLUP | INPUT_EN | MUX_MODE5) >; };	/* uart1_txd.pr1_uart0_txd */
	P2_09_pruin_pin: pinmux_P2_09_pruin_pin { pinctrl-single,pins = <
		AM33XX_IOPAD(0x0984, PIN_INPUT | MUX_MODE6) >; };			/* uart1_txd.pru0_in16 */

	/* P2_10 (ZCZ ball R14) gpio1_20 */
	P2_10_default_pin: pinmux_P2_10_default_pin { pinctrl-single,pins = <
		AM33XX_IOPAD(0x0850, PIN_OUTPUT_PULLDOWN | INPUT_EN | MUX_MODE7) >; };	/* gpmc_a4.gpio1_20 */
	P2_10_gpio_pin: pinmux_P2_10_gpio_pin { pinctrl-single,pins = <
		AM33XX_IOPAD(0x0850, PIN_OUTPUT | INPUT_EN | MUX_MODE7) >; };		/* gpmc_a4.gpio1_20 */
	P2_10_gpio_pu_pin: pinmux_P2_10_gpio_pu_pin { pinctrl-single,pins = <
		AM33XX_IOPAD(0x0850, PIN_OUTPUT_PULLUP | INPUT_EN | MUX_MODE7) >; };	/* gpmc_a4.gpio1_20 */
	P2_10_gpio_pd_pin: pinmux_P2_10_gpio_pd_pin { pinctrl-single,pins = <
		AM33XX_IOPAD(0x0850, PIN_OUTPUT_PULLDOWN | INPUT_EN | MUX_MODE7) >; };	/* gpmc_a4.gpio1_20 */
	P2_10_gpio_input_pin: pinmux_P2_10_gpio_input_pin { pinctrl-single,pins = <
		AM33XX_IOPAD(0x0850, PIN_INPUT | MUX_MODE7) >; };			/* gpmc_a4.gpio1_20 */
	P2_10_qep_pin: pinmux_P2_10_qep_pin { pinctrl-single,pins = <
		AM33XX_IOPAD(0x0850, PIN_OUTPUT_PULLUP | INPUT_EN | MUX_MODE6) >; };	/* gpmc_a4.eqep1a_in */

	/* P2_11 (ZCZ ball D16) i2c1_sda */
	P2_11_default_pin: pinmux_P2_11_default_pin { pinctrl-single,pins = <
		AM33XX_IOPAD(0x0980, PIN_OUTPUT_PULLUP | INPUT_EN | MUX_MODE3) >; };	/* uart1_rxd.i2c1_sda */
	P2_11_gpio_pin: pinmux_P2_11_gpio_pin { pinctrl-single,pins = <
		AM33XX_IOPAD(0x0980, PIN_OUTPUT | INPUT_EN | MUX_MODE7) >; };		/* uart1_rxd.gpio0_14 */
	P2_11_gpio_pu_pin: pinmux_P2_11_gpio_pu_pin { pinctrl-single,pins = <
		AM33XX_IOPAD(0x0980, PIN_OUTPUT_PULLUP | INPUT_EN | MUX_MODE7) >; };	/* uart1_rxd.gpio0_14 */
	P2_11_gpio_pd_pin: pinmux_P2_11_gpio_pd_pin { pinctrl-single,pins = <
		AM33XX_IOPAD(0x0980, PIN_OUTPUT_PULLDOWN | INPUT_EN | MUX_MODE7) >; };	/* uart1_rxd.gpio0_14 */
	P2_11_gpio_input_pin: pinmux_P2_11_gpio_input_pin { pinctrl-single,pins = <
		AM33XX_IOPAD(0x0980, PIN_INPUT | MUX_MODE7) >; };			/* uart1_rxd.gpio0_14 */
	P2_11_uart_pin: pinmux_P2_11_uart_pin { pinctrl-single,pins = <
		AM33XX_IOPAD(0x0980, PIN_OUTPUT_PULLUP | INPUT_EN | MUX_MODE0) >; };	/* uart1_rxd.uart1_rxd */
	P2_11_can_pin: pinmux_P2_11_can_pin { pinctrl-single,pins = <
		AM33XX_IOPAD(0x0980, PIN_OUTPUT_PULLUP | MUX_MODE2) >; };		/* uart1_rxd.dcan1_tx */
	P2_11_i2c_pin: pinmux_P2_11_i2c_pin { pinctrl-single,pins = <
		AM33XX_IOPAD(0x0980, PIN_OUTPUT_PULLUP | INPUT_EN | MUX_MODE3) >; };	/* uart1_rxd.i2c1_sda */
	P2_11_pru_uart_pin: pinmux_P2_11_pru_uart_pin { pinctrl-single,pins = <
		AM33XX_IOPAD(0x0980, PIN_OUTPUT_PULLUP | INPUT_EN | MUX_MODE5) >; };	/* uart1_rxd.pr1_uart0_rxd */
	P2_11_pruin_pin: pinmux_P2_11_pruin_pin { pinctrl-single,pins = <
		AM33XX_IOPAD(0x0980, PIN_INPUT | MUX_MODE6) >; };			/* uart1_rxd.pru1_in16 */

	/* P2_12                POWER_BUTTON */

	/* P2_13                VOUT-5V */

	/* P2_14                BAT-VIN */

	/* P2_15                GND */

	/* P2_16                BAT-TEMP */

	/* P2_17 (ZCZ ball V12) gpio2_1 */
	P2_17_default_pin: pinmux_P2_17_default_pin { pinctrl-single,pins = <
		AM33XX_IOPAD(0x088c, PIN_OUTPUT_PULLDOWN | INPUT_EN | MUX_MODE7) >; };	/* gpmc_clk.gpio2_1 */
	P2_17_gpio_pin: pinmux_P2_17_gpio_pin { pinctrl-single,pins = <
		AM33XX_IOPAD(0x088c, PIN_OUTPUT | INPUT_EN | MUX_MODE7) >; };		/* gpmc_clk.gpio2_1 */
	P2_17_gpio_pu_pin: pinmux_P2_17_gpio_pu_pin { pinctrl-single,pins = <
		AM33XX_IOPAD(0x088c, PIN_OUTPUT_PULLUP | INPUT_EN | MUX_MODE7) >; };	/* gpmc_clk.gpio2_1 */
	P2_17_gpio_pd_pin: pinmux_P2_17_gpio_pd_pin { pinctrl-single,pins = <
		AM33XX_IOPAD(0x088c, PIN_OUTPUT_PULLDOWN | INPUT_EN | MUX_MODE7) >; };	/* gpmc_clk.gpio2_1 */
	P2_17_gpio_input_pin: pinmux_P2_17_gpio_input_pin { pinctrl-single,pins = <
		AM33XX_IOPAD(0x088c, PIN_INPUT | MUX_MODE7) >; };			/* gpmc_clk.gpio2_1 */

	/* P2_18 (ZCZ ball U13) gpio1_15 */
	P2_18_default_pin: pinmux_P2_18_default_pin { pinctrl-single,pins = <
		AM33XX_IOPAD(0x083c, PIN_OUTPUT_PULLDOWN | INPUT_EN | MUX_MODE7) >; };	/* gpmc_ad15.gpio1_15 */
	P2_18_gpio_pin: pinmux_P2_18_gpio_pin { pinctrl-single,pins = <
		AM33XX_IOPAD(0x083c, PIN_OUTPUT | INPUT_EN | MUX_MODE7) >; };		/* gpmc_ad15.gpio1_15 */
	P2_18_gpio_pu_pin: pinmux_P2_18_gpio_pu_pin { pinctrl-single,pins = <
		AM33XX_IOPAD(0x083c, PIN_OUTPUT_PULLUP | INPUT_EN | MUX_MODE7) >; };	/* gpmc_ad15.gpio1_15 */
	P2_18_gpio_pd_pin: pinmux_P2_18_gpio_pd_pin { pinctrl-single,pins = <
		AM33XX_IOPAD(0x083c, PIN_OUTPUT_PULLDOWN | INPUT_EN | MUX_MODE7) >; };	/* gpmc_ad15.gpio1_15 */
	P2_18_gpio_input_pin: pinmux_P2_18_gpio_input_pin { pinctrl-single,pins = <
		AM33XX_IOPAD(0x083c, PIN_INPUT | MUX_MODE7) >; };			/* gpmc_ad15.gpio1_15 */
	P2_18_qep_pin: pinmux_P2_18_qep_pin { pinctrl-single,pins = <
		AM33XX_IOPAD(0x083c, PIN_OUTPUT_PULLUP | INPUT_EN | MUX_MODE4) >; };	/* gpmc_ad15.eqep2_strobe */
	P2_18_pru_ecap_pin: pinmux_P2_18_pru_ecap_pin { pinctrl-single,pins = <
		AM33XX_IOPAD(0x083c, PIN_OUTPUT_PULLDOWN | INPUT_EN | MUX_MODE5) >; };	/* gpmc_ad15.pr1_ecap0_ecap_capin_apwm_o */
	P2_18_pruin_pin: pinmux_P2_18_pruin_pin { pinctrl-single,pins = <
		AM33XX_IOPAD(0x083c, PIN_INPUT | MUX_MODE6) >; };			/* gpmc_ad15.pru0_in15 */

	/* P2_19 (ZCZ ball U12) gpio0_27 */
	P2_19_default_pin: pinmux_P2_19_default_pin { pinctrl-single,pins = <
		AM33XX_IOPAD(0x082c, PIN_OUTPUT_PULLDOWN | INPUT_EN | MUX_MODE7) >; };	/* gpmc_ad11.gpio0_27 */
	P2_19_gpio_pin: pinmux_P2_19_gpio_pin { pinctrl-single,pins = <
		AM33XX_IOPAD(0x082c, PIN_OUTPUT | INPUT_EN | MUX_MODE7) >; };		/* gpmc_ad11.gpio0_27 */
	P2_19_gpio_pu_pin: pinmux_P2_19_gpio_pu_pin { pinctrl-single,pins = <
		AM33XX_IOPAD(0x082c, PIN_OUTPUT_PULLUP | INPUT_EN | MUX_MODE7) >; };	/* gpmc_ad11.gpio0_27 */
	P2_19_gpio_pd_pin: pinmux_P2_19_gpio_pd_pin { pinctrl-single,pins = <
		AM33XX_IOPAD(0x082c, PIN_OUTPUT_PULLDOWN | INPUT_EN | MUX_MODE7) >; };	/* gpmc_ad11.gpio0_27 */
	P2_19_gpio_input_pin: pinmux_P2_19_gpio_input_pin { pinctrl-single,pins = <
		AM33XX_IOPAD(0x082c, PIN_INPUT | MUX_MODE7) >; };			/* gpmc_ad11.gpio0_27 */
	P2_19_pwm_pin: pinmux_P2_19_pwm_pin { pinctrl-single,pins = <
		AM33XX_IOPAD(0x082c, PIN_OUTPUT_PULLDOWN | INPUT_EN | MUX_MODE4) >; };	/* gpmc_ad11.ehrpwm0_synco */

	/* P2_20 (ZCZ ball T13) gpio2_0 */
	P2_20_default_pin: pinmux_P2_20_default_pin { pinctrl-single,pins = <
		AM33XX_IOPAD(0x0888, PIN_OUTPUT_PULLUP | INPUT_EN | MUX_MODE7) >; };	/* gpmc_csn3.gpio2_0 */
	P2_20_gpio_pin: pinmux_P2_20_gpio_pin { pinctrl-single,pins = <
		AM33XX_IOPAD(0x0888, PIN_OUTPUT | INPUT_EN | MUX_MODE7) >; };		/* gpmc_csn3.gpio2_0 */
	P2_20_gpio_pu_pin: pinmux_P2_20_gpio_pu_pin { pinctrl-single,pins = <
		AM33XX_IOPAD(0x0888, PIN_OUTPUT_PULLUP | INPUT_EN | MUX_MODE7) >; };	/* gpmc_csn3.gpio2_0 */
	P2_20_gpio_pd_pin: pinmux_P2_20_gpio_pd_pin { pinctrl-single,pins = <
		AM33XX_IOPAD(0x0888, PIN_OUTPUT_PULLDOWN | INPUT_EN | MUX_MODE7) >; };	/* gpmc_csn3.gpio2_0 */
	P2_20_gpio_input_pin: pinmux_P2_20_gpio_input_pin { pinctrl-single,pins = <
		AM33XX_IOPAD(0x0888, PIN_INPUT | MUX_MODE7) >; };			/* gpmc_csn3.gpio2_0 */

	/* P2_21                GND */

	/* P2_22 (ZCZ ball V13) gpio1_14 */
	P2_22_default_pin: pinmux_P2_22_default_pin { pinctrl-single,pins = <
		AM33XX_IOPAD(0x0838, PIN_OUTPUT_PULLDOWN | INPUT_EN | MUX_MODE7) >; };	/* gpmc_ad14.gpio1_14 */
	P2_22_gpio_pin: pinmux_P2_22_gpio_pin { pinctrl-single,pins = <
		AM33XX_IOPAD(0x0838, PIN_OUTPUT | INPUT_EN | MUX_MODE7) >; };		/* gpmc_ad14.gpio1_14 */
	P2_22_gpio_pu_pin: pinmux_P2_22_gpio_pu_pin { pinctrl-single,pins = <
		AM33XX_IOPAD(0x0838, PIN_OUTPUT_PULLUP | INPUT_EN | MUX_MODE7) >; };	/* gpmc_ad14.gpio1_14 */
	P2_22_gpio_pd_pin: pinmux_P2_22_gpio_pd_pin { pinctrl-single,pins = <
		AM33XX_IOPAD(0x0838, PIN_OUTPUT_PULLDOWN | INPUT_EN | MUX_MODE7) >; };	/* gpmc_ad14.gpio1_14 */
	P2_22_gpio_input_pin: pinmux_P2_22_gpio_input_pin { pinctrl-single,pins = <
		AM33XX_IOPAD(0x0838, PIN_INPUT | MUX_MODE7) >; };			/* gpmc_ad14.gpio1_14 */
	P2_22_qep_pin: pinmux_P2_22_qep_pin { pinctrl-single,pins = <
		AM33XX_IOPAD(0x0838, PIN_OUTPUT_PULLUP | INPUT_EN | MUX_MODE4) >; };	/* gpmc_ad14.eqep2_index */
	P2_22_pruin_pin: pinmux_P2_22_pruin_pin { pinctrl-single,pins = <
		AM33XX_IOPAD(0x0838, PIN_INPUT | MUX_MODE6) >; };			/* gpmc_ad14.pru0_in14 */

	/* P2_23                VOUT-3.3V */

	/* P2_24 (ZCZ ball T12) gpio1_12 */
	P2_24_default_pin: pinmux_P2_24_default_pin { pinctrl-single,pins = <
		AM33XX_IOPAD(0x0830, PIN_OUTPUT_PULLDOWN | INPUT_EN | MUX_MODE7) >; };	/* gpmc_ad12.gpio1_12 */
	P2_24_gpio_pin: pinmux_P2_24_gpio_pin { pinctrl-single,pins = <
		AM33XX_IOPAD(0x0830, PIN_OUTPUT | INPUT_EN | MUX_MODE7) >; };		/* gpmc_ad12.gpio1_12 */
	P2_24_gpio_pu_pin: pinmux_P2_24_gpio_pu_pin { pinctrl-single,pins = <
		AM33XX_IOPAD(0x0830, PIN_OUTPUT_PULLUP | INPUT_EN | MUX_MODE7) >; };	/* gpmc_ad12.gpio1_12 */
	P2_24_gpio_pd_pin: pinmux_P2_24_gpio_pd_pin { pinctrl-single,pins = <
		AM33XX_IOPAD(0x0830, PIN_OUTPUT_PULLDOWN | INPUT_EN | MUX_MODE7) >; };	/* gpmc_ad12.gpio1_12 */
	P2_24_gpio_input_pin: pinmux_P2_24_gpio_input_pin { pinctrl-single,pins = <
		AM33XX_IOPAD(0x0830, PIN_INPUT | MUX_MODE7) >; };			/* gpmc_ad12.gpio1_12 */
	P2_24_qep_pin: pinmux_P2_24_qep_pin { pinctrl-single,pins = <
		AM33XX_IOPAD(0x0830, PIN_OUTPUT_PULLUP | INPUT_EN | MUX_MODE4) >; };	/* gpmc_ad12.eqep2a_in */
	P2_24_pruout_pin: pinmux_P2_24_pruout_pin { pinctrl-single,pins = <
		AM33XX_IOPAD(0x0830, PIN_OUTPUT_PULLDOWN | INPUT_EN | MUX_MODE6) >; };	/* gpmc_ad12.pru0_out14 */

	/* P2_25 (ZCZ ball E17) spi1_d1 */
	P2_25_default_pin: pinmux_P2_25_default_pin { pinctrl-single,pins = <
		AM33XX_IOPAD(0x096c, PIN_OUTPUT_PULLUP | INPUT_EN | MUX_MODE4) >; };	/* uart0_rtsn.spi1_d1 */
	P2_25_gpio_pin: pinmux_P2_25_gpio_pin { pinctrl-single,pins = <
		AM33XX_IOPAD(0x096c, PIN_OUTPUT | INPUT_EN | MUX_MODE7) >; };		/* uart0_rtsn.gpio1_9 */
	P2_25_gpio_pu_pin: pinmux_P2_25_gpio_pu_pin { pinctrl-single,pins = <
		AM33XX_IOPAD(0x096c, PIN_OUTPUT_PULLUP | INPUT_EN | MUX_MODE7) >; };	/* uart0_rtsn.gpio1_9 */
	P2_25_gpio_pd_pin: pinmux_P2_25_gpio_pd_pin { pinctrl-single,pins = <
		AM33XX_IOPAD(0x096c, PIN_OUTPUT_PULLDOWN | INPUT_EN | MUX_MODE7) >; };	/* uart0_rtsn.gpio1_9 */
	P2_25_gpio_input_pin: pinmux_P2_25_gpio_input_pin { pinctrl-single,pins = <
		AM33XX_IOPAD(0x096c, PIN_INPUT | MUX_MODE7) >; };			/* uart0_rtsn.gpio1_9 */
	P2_25_uart_pin: pinmux_P2_25_uart_pin { pinctrl-single,pins = <
		AM33XX_IOPAD(0x096c, PIN_OUTPUT_PULLUP | INPUT_EN | MUX_MODE1) >; };	/* uart0_rtsn.uart4_txd */
	P2_25_can_pin: pinmux_P2_25_can_pin { pinctrl-single,pins = <
		AM33XX_IOPAD(0x096c, PIN_INPUT_PULLUP | MUX_MODE2) >; };		/* uart0_rtsn.dcan1_rx */
	P2_25_i2c_pin: pinmux_P2_25_i2c_pin { pinctrl-single,pins = <
		AM33XX_IOPAD(0x096c, PIN_OUTPUT_PULLUP | INPUT_EN | MUX_MODE3) >; };	/* uart0_rtsn.i2c1_scl */
	P2_25_spi_pin: pinmux_P2_25_spi_pin { pinctrl-single,pins = <
		AM33XX_IOPAD(0x096c, PIN_OUTPUT_PULLUP | INPUT_EN | MUX_MODE4) >; };	/* uart0_rtsn.spi1_d1 */
	P2_25_spi_cs_pin: pinmux_P2_25_spi_cs_pin { pinctrl-single,pins = <
		AM33XX_IOPAD(0x096c, PIN_OUTPUT_PULLUP | INPUT_EN | MUX_MODE5) >; };	/* uart0_rtsn.spi1_cs0 */

	/* P2_26                RESET# */

	/* P2_27 (ZCZ ball E18) spi1_d0 */
	P2_27_default_pin: pinmux_P2_27_default_pin { pinctrl-single,pins = <
		AM33XX_IOPAD(0x0968, PIN_OUTPUT_PULLUP | INPUT_EN | MUX_MODE4) >; };	/* uart0_ctsn.spi1_d0 */
	P2_27_gpio_pin: pinmux_P2_27_gpio_pin { pinctrl-single,pins = <
		AM33XX_IOPAD(0x0968, PIN_OUTPUT | INPUT_EN | MUX_MODE7) >; };		/* uart0_ctsn.gpio1_8 */
	P2_27_gpio_pu_pin: pinmux_P2_27_gpio_pu_pin { pinctrl-single,pins = <
		AM33XX_IOPAD(0x0968, PIN_OUTPUT_PULLUP | INPUT_EN | MUX_MODE7) >; };	/* uart0_ctsn.gpio1_8 */
	P2_27_gpio_pd_pin: pinmux_P2_27_gpio_pd_pin { pinctrl-single,pins = <
		AM33XX_IOPAD(0x0968, PIN_OUTPUT_PULLDOWN | INPUT_EN | MUX_MODE7) >; };	/* uart0_ctsn.gpio1_8 */
	P2_27_gpio_input_pin: pinmux_P2_27_gpio_input_pin { pinctrl-single,pins = <
		AM33XX_IOPAD(0x0968, PIN_INPUT | MUX_MODE7) >; };			/* uart0_ctsn.gpio1_8 */
	P2_27_uart_pin: pinmux_P2_27_uart_pin { pinctrl-single,pins = <
		AM33XX_IOPAD(0x0968, PIN_OUTPUT_PULLUP | INPUT_EN | MUX_MODE1) >; };	/* uart0_ctsn.uart4_rxd */
	P2_27_can_pin: pinmux_P2_27_can_pin { pinctrl-single,pins = <
		AM33XX_IOPAD(0x0968, PIN_OUTPUT_PULLUP | MUX_MODE2) >; };		/* uart0_ctsn.dcan1_tx */
	P2_27_i2c_pin: pinmux_P2_27_i2c_pin { pinctrl-single,pins = <
		AM33XX_IOPAD(0x0968, PIN_OUTPUT_PULLUP | INPUT_EN | MUX_MODE3) >; };	/* uart0_ctsn.i2c1_sda */
	P2_27_spi_pin: pinmux_P2_27_spi_pin { pinctrl-single,pins = <
		AM33XX_IOPAD(0x0968, PIN_OUTPUT_PULLUP | INPUT_EN | MUX_MODE4) >; };	/* uart0_ctsn.spi1_d0 */

	/* P2_28 (ZCZ ball D13) pru0_in6 */
	P2_28_default_pin: pinmux_P2_28_default_pin { pinctrl-single,pins = <
		AM33XX_IOPAD(0x09a8, PIN_INPUT | MUX_MODE6) >; };			/* mcasp0_axr1.pru0_in6 */
	P2_28_gpio_pin: pinmux_P2_28_gpio_pin { pinctrl-single,pins = <
		AM33XX_IOPAD(0x09a8, PIN_OUTPUT | INPUT_EN | MUX_MODE7) >; };		/* mcasp0_axr1.gpio3_20 */
	P2_28_gpio_pu_pin: pinmux_P2_28_gpio_pu_pin { pinctrl-single,pins = <
		AM33XX_IOPAD(0x09a8, PIN_OUTPUT_PULLUP | INPUT_EN | MUX_MODE7) >; };	/* mcasp0_axr1.gpio3_20 */
	P2_28_gpio_pd_pin: pinmux_P2_28_gpio_pd_pin { pinctrl-single,pins = <
		AM33XX_IOPAD(0x09a8, PIN_OUTPUT_PULLDOWN | INPUT_EN | MUX_MODE7) >; };	/* mcasp0_axr1.gpio3_20 */
	P2_28_gpio_input_pin: pinmux_P2_28_gpio_input_pin { pinctrl-single,pins = <
		AM33XX_IOPAD(0x09a8, PIN_INPUT | MUX_MODE7) >; };			/* mcasp0_axr1.gpio3_20 */
	P2_28_qep_pin: pinmux_P2_28_qep_pin { pinctrl-single,pins = <
		AM33XX_IOPAD(0x09a8, PIN_OUTPUT_PULLUP | INPUT_EN | MUX_MODE1) >; };	/* mcasp0_axr1.eqep0_index */
	P2_28_pruout_pin: pinmux_P2_28_pruout_pin { pinctrl-single,pins = <
		AM33XX_IOPAD(0x09a8, PIN_OUTPUT_PULLDOWN | INPUT_EN | MUX_MODE5) >; };	/* mcasp0_axr1.pru0_out6 */
	P2_28_pruin_pin: pinmux_P2_28_pruin_pin { pinctrl-single,pins = <
		AM33XX_IOPAD(0x09a8, PIN_INPUT | MUX_MODE6) >; };			/* mcasp0_axr1.pru0_in6 */

	/* P2_29 (ZCZ ball C18) spi1_sclk */
	P2_29_default_pin: pinmux_P2_29_default_pin { pinctrl-single,pins = <
		AM33XX_IOPAD(0x0964, PIN_OUTPUT_PULLUP | INPUT_EN | MUX_MODE4) >; };	/* eCAP0_in_PWM0_out.spi1_sclk */
	P2_29_gpio_pin: pinmux_P2_29_gpio_pin { pinctrl-single,pins = <
		AM33XX_IOPAD(0x0964, PIN_OUTPUT | INPUT_EN | MUX_MODE7) >; };		/* eCAP0_in_PWM0_out.gpio0_7 */
	P2_29_gpio_pu_pin: pinmux_P2_29_gpio_pu_pin { pinctrl-single,pins = <
		AM33XX_IOPAD(0x0964, PIN_OUTPUT_PULLUP | INPUT_EN | MUX_MODE7) >; };	/* eCAP0_in_PWM0_out.gpio0_7 */
	P2_29_gpio_pd_pin: pinmux_P2_29_gpio_pd_pin { pinctrl-single,pins = <
		AM33XX_IOPAD(0x0964, PIN_OUTPUT_PULLDOWN | INPUT_EN | MUX_MODE7) >; };	/* eCAP0_in_PWM0_out.gpio0_7 */
	P2_29_gpio_input_pin: pinmux_P2_29_gpio_input_pin { pinctrl-single,pins = <
		AM33XX_IOPAD(0x0964, PIN_INPUT | MUX_MODE7) >; };			/* eCAP0_in_PWM0_out.gpio0_7 */
	P2_29_pwm_pin: pinmux_P2_29_pwm_pin { pinctrl-single,pins = <
		AM33XX_IOPAD(0x0964, PIN_OUTPUT_PULLDOWN | INPUT_EN | MUX_MODE0) >; };	/* eCAP0_in_PWM0_out.ecap0_in_pwm0_out */
	P2_29_uart_pin: pinmux_P2_29_uart_pin { pinctrl-single,pins = <
		AM33XX_IOPAD(0x0964, PIN_OUTPUT_PULLUP | INPUT_EN | MUX_MODE1) >; };	/* eCAP0_in_PWM0_out.uart3_txd */
	P2_29_spi_cs_pin: pinmux_P2_29_spi_cs_pin { pinctrl-single,pins = <
		AM33XX_IOPAD(0x0964, PIN_OUTPUT_PULLUP | INPUT_EN | MUX_MODE2) >; };	/* eCAP0_in_PWM0_out.spi1_cs1 */
	P2_29_pru_ecap_pin: pinmux_P2_29_pru_ecap_pin { pinctrl-single,pins = <
		AM33XX_IOPAD(0x0964, PIN_OUTPUT_PULLDOWN | INPUT_EN | MUX_MODE3) >; };	/* eCAP0_in_PWM0_out.pr1_ecap0_ecap_capin_apwm_o */
	P2_29_spi_sclk_pin: pinmux_P2_29_spi_sclk_pin { pinctrl-single,pins = <
		AM33XX_IOPAD(0x0964, PIN_OUTPUT_PULLUP | INPUT_EN | MUX_MODE4) >; };	/* eCAP0_in_PWM0_out.spi1_sclk */

	/* P2_30 (ZCZ ball C12) pru0_in3 */
	P2_30_default_pin: pinmux_P2_30_default_pin { pinctrl-single,pins = <
		AM33XX_IOPAD(0x099c, PIN_INPUT | MUX_MODE6) >; };			/* mcasp0_ahclkr.pru0_in3 */
	P2_30_gpio_pin: pinmux_P2_30_gpio_pin { pinctrl-single,pins = <
		AM33XX_IOPAD(0x099c, PIN_OUTPUT | INPUT_EN | MUX_MODE7) >; };		/* mcasp0_ahclkr.gpio3_17 */
	P2_30_gpio_pu_pin: pinmux_P2_30_gpio_pu_pin { pinctrl-single,pins = <
		AM33XX_IOPAD(0x099c, PIN_OUTPUT_PULLUP | INPUT_EN | MUX_MODE7) >; };	/* mcasp0_ahclkr.gpio3_17 */
	P2_30_gpio_pd_pin: pinmux_P2_30_gpio_pd_pin { pinctrl-single,pins = <
		AM33XX_IOPAD(0x099c, PIN_OUTPUT_PULLDOWN | INPUT_EN | MUX_MODE7) >; };	/* mcasp0_ahclkr.gpio3_17 */
	P2_30_gpio_input_pin: pinmux_P2_30_gpio_input_pin { pinctrl-single,pins = <
		AM33XX_IOPAD(0x099c, PIN_INPUT | MUX_MODE7) >; };			/* mcasp0_ahclkr.gpio3_17 */
	P2_30_pwm_pin: pinmux_P2_30_pwm_pin { pinctrl-single,pins = <
		AM33XX_IOPAD(0x099c, PIN_OUTPUT_PULLDOWN | INPUT_EN | MUX_MODE1) >; };	/* mcasp0_ahclkr.ehrpwm0_synci */
	P2_30_spi_cs_pin: pinmux_P2_30_spi_cs_pin { pinctrl-single,pins = <
		AM33XX_IOPAD(0x099c, PIN_OUTPUT_PULLUP | INPUT_EN | MUX_MODE3) >; };	/* mcasp0_ahclkr.spi1_cs0 */
	P2_30_pruout_pin: pinmux_P2_30_pruout_pin { pinctrl-single,pins = <
		AM33XX_IOPAD(0x099c, PIN_OUTPUT_PULLDOWN | INPUT_EN | MUX_MODE5) >; };	/* mcasp0_ahclkr.pru0_out3 */
	P2_30_pruin_pin: pinmux_P2_30_pruin_pin { pinctrl-single,pins = <
		AM33XX_IOPAD(0x099c, PIN_INPUT | MUX_MODE6) >; };			/* mcasp0_ahclkr.pru0_in3 */

	/* P2_31 (ZCZ ball A15) spi1_cs1 */
	P2_31_default_pin: pinmux_P2_31_default_pin { pinctrl-single,pins = <
		AM33XX_IOPAD(0x09b0, PIN_OUTPUT_PULLUP | INPUT_EN | MUX_MODE4) >; };	/* xdma_event_intr0.spi1_cs1 */
	P2_31_gpio_pin: pinmux_P2_31_gpio_pin { pinctrl-single,pins = <
		AM33XX_IOPAD(0x09b0, PIN_OUTPUT | INPUT_EN | MUX_MODE7) >; };		/* xdma_event_intr0.gpio0_19 */
	P2_31_gpio_pu_pin: pinmux_P2_31_gpio_pu_pin { pinctrl-single,pins = <
		AM33XX_IOPAD(0x09b0, PIN_OUTPUT_PULLUP | INPUT_EN | MUX_MODE7) >; };	/* xdma_event_intr0.gpio0_19 */
	P2_31_gpio_pd_pin: pinmux_P2_31_gpio_pd_pin { pinctrl-single,pins = <
		AM33XX_IOPAD(0x09b0, PIN_OUTPUT_PULLDOWN | INPUT_EN | MUX_MODE7) >; };	/* xdma_event_intr0.gpio0_19 */
	P2_31_gpio_input_pin: pinmux_P2_31_gpio_input_pin { pinctrl-single,pins = <
		AM33XX_IOPAD(0x09b0, PIN_INPUT | MUX_MODE7) >; };			/* xdma_event_intr0.gpio0_19 */
	P2_31_spi_cs_pin: pinmux_P2_31_spi_cs_pin { pinctrl-single,pins = <
		AM33XX_IOPAD(0x09b0, PIN_OUTPUT_PULLUP | INPUT_EN | MUX_MODE4) >; };	/* xdma_event_intr0.spi1_cs1 */
	P2_31_pruin_pin: pinmux_P2_31_pruin_pin { pinctrl-single,pins = <
		AM33XX_IOPAD(0x09b0, PIN_INPUT | MUX_MODE5) >; };			/* xdma_event_intr0.pru1_in16 */

	/* P2_32 (ZCZ ball D12) pru0_in2 */
	P2_32_default_pin: pinmux_P2_32_default_pin { pinctrl-single,pins = <
		AM33XX_IOPAD(0x0998, PIN_INPUT | MUX_MODE6) >; };			/* mcasp0_axr0.pru0_in2 */
	P2_32_gpio_pin: pinmux_P2_32_gpio_pin { pinctrl-single,pins = <
		AM33XX_IOPAD(0x0998, PIN_OUTPUT | INPUT_EN | MUX_MODE7) >; };		/* mcasp0_axr0.gpio3_16 */
	P2_32_gpio_pu_pin: pinmux_P2_32_gpio_pu_pin { pinctrl-single,pins = <
		AM33XX_IOPAD(0x0998, PIN_OUTPUT_PULLUP | INPUT_EN | MUX_MODE7) >; };	/* mcasp0_axr0.gpio3_16 */
	P2_32_gpio_pd_pin: pinmux_P2_32_gpio_pd_pin { pinctrl-single,pins = <
		AM33XX_IOPAD(0x0998, PIN_OUTPUT_PULLDOWN | INPUT_EN | MUX_MODE7) >; };	/* mcasp0_axr0.gpio3_16 */
	P2_32_gpio_input_pin: pinmux_P2_32_gpio_input_pin { pinctrl-single,pins = <
		AM33XX_IOPAD(0x0998, PIN_INPUT | MUX_MODE7) >; };			/* mcasp0_axr0.gpio3_16 */
	P2_32_pwm_pin: pinmux_P2_32_pwm_pin { pinctrl-single,pins = <
		AM33XX_IOPAD(0x0998, PIN_OUTPUT_PULLDOWN | INPUT_EN | MUX_MODE1) >; };	/* mcasp0_axr0.ehrpwm0_tripzone_input */
	P2_32_spi_pin: pinmux_P2_32_spi_pin { pinctrl-single,pins = <
		AM33XX_IOPAD(0x0998, PIN_OUTPUT_PULLUP | INPUT_EN | MUX_MODE3) >; };	/* mcasp0_axr0.spi1_d1 */
	P2_32_pruout_pin: pinmux_P2_32_pruout_pin { pinctrl-single,pins = <
		AM33XX_IOPAD(0x0998, PIN_OUTPUT_PULLDOWN | INPUT_EN | MUX_MODE5) >; };	/* mcasp0_axr0.pru0_out2 */
	P2_32_pruin_pin: pinmux_P2_32_pruin_pin { pinctrl-single,pins = <
		AM33XX_IOPAD(0x0998, PIN_INPUT | MUX_MODE6) >; };			/* mcasp0_axr0.pru0_in2 */

	/* P2_33 (ZCZ ball R12) gpio1_13 */
	P2_33_default_pin: pinmux_P2_33_default_pin { pinctrl-single,pins = <
		AM33XX_IOPAD(0x0834, PIN_OUTPUT_PULLDOWN | INPUT_EN | MUX_MODE7) >; };	/* gpmc_ad13.gpio1_13 */
	P2_33_gpio_pin: pinmux_P2_33_gpio_pin { pinctrl-single,pins = <
		AM33XX_IOPAD(0x0834, PIN_OUTPUT | INPUT_EN | MUX_MODE7) >; };		/* gpmc_ad13.gpio1_13 */
	P2_33_gpio_pu_pin: pinmux_P2_33_gpio_pu_pin { pinctrl-single,pins = <
		AM33XX_IOPAD(0x0834, PIN_OUTPUT_PULLUP | INPUT_EN | MUX_MODE7) >; };	/* gpmc_ad13.gpio1_13 */
	P2_33_gpio_pd_pin: pinmux_P2_33_gpio_pd_pin { pinctrl-single,pins = <
		AM33XX_IOPAD(0x0834, PIN_OUTPUT_PULLDOWN | INPUT_EN | MUX_MODE7) >; };	/* gpmc_ad13.gpio1_13 */
	P2_33_gpio_input_pin: pinmux_P2_33_gpio_input_pin { pinctrl-single,pins = <
		AM33XX_IOPAD(0x0834, PIN_INPUT | MUX_MODE7) >; };			/* gpmc_ad13.gpio1_13 */
	P2_33_qep_pin: pinmux_P2_33_qep_pin { pinctrl-single,pins = <
		AM33XX_IOPAD(0x0834, PIN_OUTPUT_PULLUP | INPUT_EN | MUX_MODE4) >; };	/* gpmc_ad13.eqep2b_in */
	P2_33_pruout_pin: pinmux_P2_33_pruout_pin { pinctrl-single,pins = <
		AM33XX_IOPAD(0x0834, PIN_OUTPUT_PULLDOWN | INPUT_EN | MUX_MODE6) >; };	/* gpmc_ad13.pru0_out15 */

	/* P2_34 (ZCZ ball C13) pru0_in5 */
	P2_34_default_pin: pinmux_P2_34_default_pin { pinctrl-single,pins = <
		AM33XX_IOPAD(0x09a4, PIN_INPUT | MUX_MODE6) >; };			/* mcasp0_fsr.pru0_in5 */
	P2_34_gpio_pin: pinmux_P2_34_gpio_pin { pinctrl-single,pins = <
		AM33XX_IOPAD(0x09a4, PIN_OUTPUT | INPUT_EN | MUX_MODE7) >; };		/* mcasp0_fsr.gpio3_19 */
	P2_34_gpio_pu_pin: pinmux_P2_34_gpio_pu_pin { pinctrl-single,pins = <
		AM33XX_IOPAD(0x09a4, PIN_OUTPUT_PULLUP | INPUT_EN | MUX_MODE7) >; };	/* mcasp0_fsr.gpio3_19 */
	P2_34_gpio_pd_pin: pinmux_P2_34_gpio_pd_pin { pinctrl-single,pins = <
		AM33XX_IOPAD(0x09a4, PIN_OUTPUT_PULLDOWN | INPUT_EN | MUX_MODE7) >; };	/* mcasp0_fsr.gpio3_19 */
	P2_34_gpio_input_pin: pinmux_P2_34_gpio_input_pin { pinctrl-single,pins = <
		AM33XX_IOPAD(0x09a4, PIN_INPUT | MUX_MODE7) >; };			/* mcasp0_fsr.gpio3_19 */
	P2_34_qep_pin: pinmux_P2_34_qep_pin { pinctrl-single,pins = <
		AM33XX_IOPAD(0x09a4, PIN_OUTPUT_PULLUP | INPUT_EN | MUX_MODE1) >; };	/* mcasp0_fsr.eqep0b_in */
	P2_34_pruout_pin: pinmux_P2_34_pruout_pin { pinctrl-single,pins = <
		AM33XX_IOPAD(0x09a4, PIN_OUTPUT_PULLDOWN | INPUT_EN | MUX_MODE5) >; };	/* mcasp0_fsr.pru0_out5 */
	P2_34_pruin_pin: pinmux_P2_34_pruin_pin { pinctrl-single,pins = <
		AM33XX_IOPAD(0x09a4, PIN_INPUT | MUX_MODE6) >; };			/* mcasp0_fsr.pru0_in5 */

	/* P2_35 (ZCZ ball U5) gpio2_22 */
	P2_35_default_pin: pinmux_P2_35_default_pin { pinctrl-single,pins = <
		AM33XX_IOPAD(0x08e0, PIN_INPUT | MUX_MODE7) >; };			/* lcd_vsync.gpio2_22 */
	P2_35_gpio_pin: pinmux_P2_35_gpio_pin { pinctrl-single,pins = <
		AM33XX_IOPAD(0x08e0, PIN_OUTPUT | INPUT_EN | MUX_MODE7) >; };		/* lcd_vsync.gpio2_22 */
	P2_35_gpio_pu_pin: pinmux_P2_35_gpio_pu_pin { pinctrl-single,pins = <
		AM33XX_IOPAD(0x08e0, PIN_OUTPUT_PULLUP | INPUT_EN | MUX_MODE7) >; };	/* lcd_vsync.gpio2_22 */
	P2_35_gpio_pd_pin: pinmux_P2_35_gpio_pd_pin { pinctrl-single,pins = <
		AM33XX_IOPAD(0x08e0, PIN_OUTPUT_PULLDOWN | INPUT_EN | MUX_MODE7) >; };	/* lcd_vsync.gpio2_22 */
	P2_35_gpio_input_pin: pinmux_P2_35_gpio_input_pin { pinctrl-single,pins = <
		AM33XX_IOPAD(0x08e0, PIN_INPUT | MUX_MODE7) >; };			/* lcd_vsync.gpio2_22 */
	P2_35_pruout_pin: pinmux_P2_35_pruout_pin { pinctrl-single,pins = <
		AM33XX_IOPAD(0x08e0, PIN_OUTPUT_PULLDOWN | INPUT_EN | MUX_MODE5) >; };	/* lcd_vsync.pru1_out8 */
	P2_35_pruin_pin: pinmux_P2_35_pruin_pin { pinctrl-single,pins = <
		AM33XX_IOPAD(0x08e0, PIN_INPUT | MUX_MODE6) >; };			/* lcd_vsync.pru1_in8 */

	/* P2_36 (ZCZ ball C9)  AIN7         */
};

&uart0 {
	status = "okay";
	pinctrl-names = "default";
	pinctrl-0 = <>;
};

&uart1 {
	status = "okay";
	pinctrl-names = "default";
	pinctrl-0 = <>;
};

&uart2 {
	status = "okay";
	pinctrl-names = "default";
	pinctrl-0 = <>;
};

&uart4 {
	status = "okay";
	pinctrl-names = "default";
	pinctrl-0 = <>;
};

&usb {
	status = "okay";
};

&usb_ctrl_mod {
	status = "okay";
};

&usb0_phy {
	status = "okay";
};

&usb0 {
	status = "okay";
	dr_mode = "otg";
};

&usb1_phy {
	status = "okay";
};

&usb1 {
	status = "okay";
	dr_mode = "host";
};

&cppi41dma  {
	status = "okay";
};

&i2c0 {
	pinctrl-names = "default";
	pinctrl-0 = <&i2c0_pins>;

	status = "okay";
	clock-frequency = <400000>;

	tps: tps@24 {
		reg = <0x24>;
	};

	baseboard_eeprom: baseboard_eeprom@50 {
		compatible = "atmel,24c256";
		reg = <0x50>;

		#address-cells = <1>;
		#size-cells = <1>;
		baseboard_data: baseboard_data@0 {
			reg = <0 0x100>;
		};
	};
};

&i2c1 {
	#address-cells = <1>;
	#size-cells = <0>;
	status = "okay";
	clock-frequency = <400000>;
};

&i2c2 {
	#address-cells = <1>;
	#size-cells = <0>;
	status = "okay";
	clock-frequency = <400000>;
};

/include/ "tps65217.dtsi"

&tps {
	interrupts = <7>; /* NMI */
	interrupt-parent = <&intc>;

	ti,pmic-shutdown-controller;

	charger {
		status = "okay";
	};

	pwrbutton {
		status = "okay";
	};

	regulators {
		dcdc1_reg: regulator@0 {
			regulator-name = "vdds_dpr";
			regulator-always-on;
		};

		dcdc2_reg: regulator@1 {
			/* VDD_MPU voltage limits 0.95V - 1.26V with +/-4% tolerance */
			regulator-name = "vdd_mpu";
			regulator-min-microvolt = <925000>;
			regulator-max-microvolt = <1351500>;
			regulator-boot-on;
			regulator-always-on;
		};

		dcdc3_reg: regulator@2 {
			/* VDD_CORE voltage limits 0.95V - 1.1V with +/-4% tolerance */
			regulator-name = "vdd_core";
			regulator-min-microvolt = <925000>;
			regulator-max-microvolt = <1150000>;
			regulator-boot-on;
			regulator-always-on;
		};

		ldo1_reg: regulator@3 {
			regulator-name = "vio,vrtc,vdds";
			regulator-always-on;
		};

		ldo2_reg: regulator@4 {
			regulator-name = "vdd_3v3aux";
			regulator-always-on;
		};

		ldo3_reg: regulator@5 {
			regulator-name = "vdd_1v8";
			regulator-min-microvolt = <1800000>;
			regulator-max-microvolt = <1800000>;
			regulator-always-on;
		};

		ldo4_reg: regulator@6 {
			regulator-name = "vdd_3v3a";
			regulator-always-on;
		};
	};
};

&tscadc {
	status = "okay";
	adc {
		ti,adc-channels = <0 1 2 3 4 5 6 7>;
		ti,chan-step-avg = <0x16 0x16 0x16 0x16 0x16 0x16 0x16 0x16>;
		ti,chan-step-opendelay = <0x98 0x98 0x98 0x98 0x98 0x98 0x98 0x98>;
		ti,chan-step-sampledelay = <0x0 0x0 0x0 0x0 0x0 0x0 0x0 0x0>;
	};
};

&mmc1 {
	status = "okay";
	vmmc-supply = <&vmmcsd_fixed>;
	bus-width = <4>;
	pinctrl-names = "default";
	pinctrl-0 = <&mmc0_pins>;
	cd-gpios = <&gpio0 6 GPIO_ACTIVE_LOW>;
};

&aes {
	status = "okay";
};

&sham {
	status = "okay";
};

&rtc {
	system-power-controller;
};

&pruss_soc_bus {
	status = "okay";

	pruss: pruss@0 {
		status = "okay";
	};
};

&epwmss0 {
	status = "okay";
};

&ehrpwm0 {
	status = "okay";
	pinctrl-names = "default";
	pinctrl-0 = <>;
};

&epwmss1 {
	status = "okay";
};

&ehrpwm1 {
	status = "okay";
	pinctrl-names = "default";
	pinctrl-0 = <>;
};

&epwmss2 {
	status = "okay";
};

&ehrpwm2 {
	status = "okay";
	pinctrl-names = "default";
	pinctrl-0 = <>;
};

&dcan0 {
	status = "okay";
	pinctrl-names = "default";
	pinctrl-0 = <>;
};

&dcan1 {
	status = "okay";
	pinctrl-names = "default";
	pinctrl-0 = <>;
};
